VERSION ""

NS_ :

BS_:
BU_: BMC CMC_01 CMC_02 CMC_03 CMC_04 CMC_05 CMC_06 CMC_07 CMC_08 P2_CMC_01 HVBatteryController
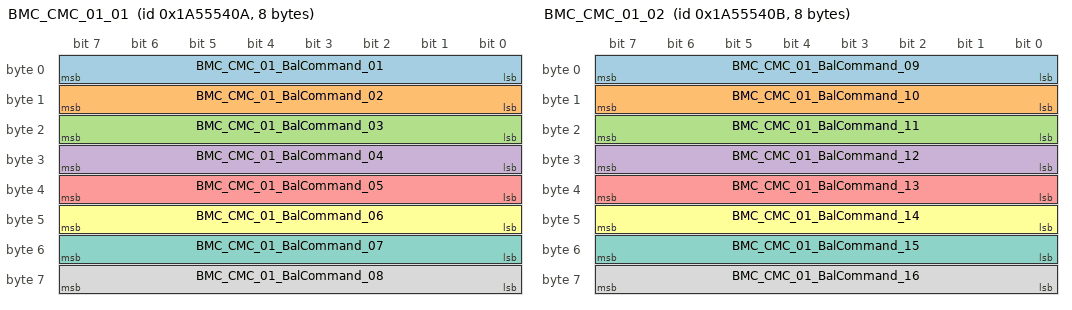
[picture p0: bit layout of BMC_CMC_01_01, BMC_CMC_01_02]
BO_ 441799690 BMC_CMC_01_01: 8 BMC
   SG_ BMC_CMC_01_BalCommand_01 : 0|8@1+ (2,0) [0|506] "Minute" CMC_01
   SG_ BMC_CMC_01_BalCommand_02 : 8|8@1+ (2,0) [0|506] "Minute" CMC_01
   SG_ BMC_CMC_01_BalCommand_03 : 16|8@1+ (2,0) [0|506] "Minute" CMC_01
   SG_ BMC_CMC_01_BalCommand_04 : 24|8@1+ (2,0) [0|506] "Minute" CMC_01
   SG_ BMC_CMC_01_BalCommand_05 : 32|8@1+ (2,0) [0|506] "Minute" CMC_01
   SG_ BMC_CMC_01_BalCommand_06 : 40|8@1+ (2,0) [0|506] "Minute" CMC_01
   SG_ BMC_CMC_01_BalCommand_07 : 48|8@1+ (2,0) [0|506] "Minute" CMC_01
   SG_ BMC_CMC_01_BalCommand_08 : 56|8@1+ (2,0) [0|506] "Minute" CMC_01

BO_ 441799691 BMC_CMC_01_02: 8 BMC
   SG_ BMC_CMC_01_BalCommand_09 : 0|8@1+ (2,0) [0|506] "Minute" CMC_01
   SG_ BMC_CMC_01_BalCommand_10 : 8|8@1+ (2,0) [0|506] "Minute" CMC_01
   SG_ BMC_CMC_01_BalCommand_11 : 16|8@1+ (2,0) [0|506] "Minute" CMC_01
   SG_ BMC_CMC_01_BalCommand_12 : 24|8@1+ (2,0) [0|506] "Minute" CMC_01
   SG_ BMC_CMC_01_BalCommand_13 : 32|8@1+ (2,0) [0|506] "Minute" CMC_01
   SG_ BMC_CMC_01_BalCommand_14 : 40|8@1+ (2,0) [0|506] "Minute" CMC_01
   SG_ BMC_CMC_01_BalCommand_15 : 48|8@1+ (2,0) [0|506] "Minute" CMC_01
   SG_ BMC_CMC_01_BalCommand_16 : 56|8@1+ (2,0) [0|506] "Minute" CMC_01

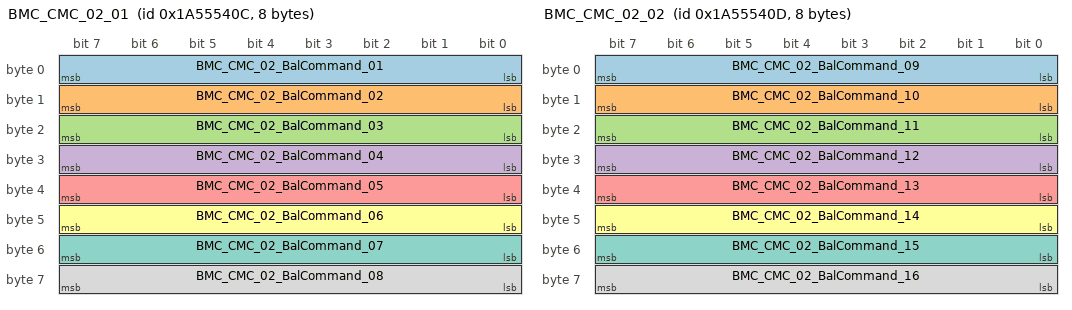
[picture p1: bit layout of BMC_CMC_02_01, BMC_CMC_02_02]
BO_ 441799692 BMC_CMC_02_01: 8 BMC
   SG_ BMC_CMC_02_BalCommand_01 : 0|8@1+ (2,0) [0|506] "Minute" CMC_02
   SG_ BMC_CMC_02_BalCommand_02 : 8|8@1+ (2,0) [0|506] "Minute" CMC_02
   SG_ BMC_CMC_02_BalCommand_03 : 16|8@1+ (2,0) [0|506] "Minute" CMC_02
   SG_ BMC_CMC_02_BalCommand_04 : 24|8@1+ (2,0) [0|506] "Minute" CMC_02
   SG_ BMC_CMC_02_BalCommand_05 : 32|8@1+ (2,0) [0|506] "Minute" CMC_02
   SG_ BMC_CMC_02_BalCommand_06 : 40|8@1+ (2,0) [0|506] "Minute" CMC_02
   SG_ BMC_CMC_02_BalCommand_07 : 48|8@1+ (2,0) [0|506] "Minute" CMC_02
   SG_ BMC_CMC_02_BalCommand_08 : 56|8@1+ (2,0) [0|506] "Minute" CMC_02

BO_ 441799693 BMC_CMC_02_02: 8 BMC
   SG_ BMC_CMC_02_BalCommand_09 : 0|8@1+ (2,0) [0|506] "Minute" CMC_02
   SG_ BMC_CMC_02_BalCommand_10 : 8|8@1+ (2,0) [0|506] "Minute" CMC_02
   SG_ BMC_CMC_02_BalCommand_11 : 16|8@1+ (2,0) [0|506] "Minute" CMC_02
   SG_ BMC_CMC_02_BalCommand_12 : 24|8@1+ (2,0) [0|506] "Minute" CMC_02
   SG_ BMC_CMC_02_BalCommand_13 : 32|8@1+ (2,0) [0|506] "Minute" CMC_02
   SG_ BMC_CMC_02_BalCommand_14 : 40|8@1+ (2,0) [0|506] "Minute" CMC_02
   SG_ BMC_CMC_02_BalCommand_15 : 48|8@1+ (2,0) [0|506] "Minute" CMC_02
   SG_ BMC_CMC_02_BalCommand_16 : 56|8@1+ (2,0) [0|506] "Minute" CMC_02

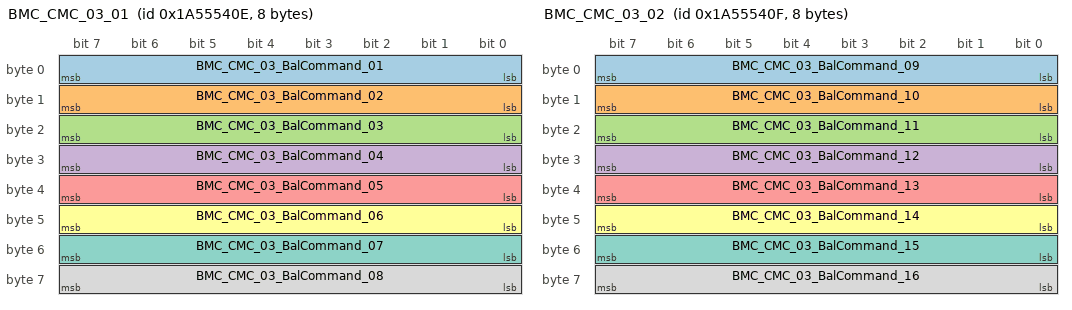
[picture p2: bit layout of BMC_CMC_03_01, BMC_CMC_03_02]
BO_ 441799694 BMC_CMC_03_01: 8 BMC
   SG_ BMC_CMC_03_BalCommand_01 : 0|8@1+ (2,0) [0|506] "Minute" CMC_03
   SG_ BMC_CMC_03_BalCommand_02 : 8|8@1+ (2,0) [0|506] "Minute" CMC_03
   SG_ BMC_CMC_03_BalCommand_03 : 16|8@1+ (2,0) [0|506] "Minute" CMC_03
   SG_ BMC_CMC_03_BalCommand_04 : 24|8@1+ (2,0) [0|506] "Minute" CMC_03
   SG_ BMC_CMC_03_BalCommand_05 : 32|8@1+ (2,0) [0|506] "Minute" CMC_03
   SG_ BMC_CMC_03_BalCommand_06 : 40|8@1+ (2,0) [0|506] "Minute" CMC_03
   SG_ BMC_CMC_03_BalCommand_07 : 48|8@1+ (2,0) [0|506] "Minute" CMC_03
   SG_ BMC_CMC_03_BalCommand_08 : 56|8@1+ (2,0) [0|506] "Minute" CMC_03

BO_ 441799695 BMC_CMC_03_02: 8 BMC
   SG_ BMC_CMC_03_BalCommand_09 : 0|8@1+ (2,0) [0|506] "Minute" CMC_03
   SG_ BMC_CMC_03_BalCommand_10 : 8|8@1+ (2,0) [0|506] "Minute" CMC_03
   SG_ BMC_CMC_03_BalCommand_11 : 16|8@1+ (2,0) [0|506] "Minute" CMC_03
   SG_ BMC_CMC_03_BalCommand_12 : 24|8@1+ (2,0) [0|506] "Minute" CMC_03
   SG_ BMC_CMC_03_BalCommand_13 : 32|8@1+ (2,0) [0|506] "Minute" CMC_03
   SG_ BMC_CMC_03_BalCommand_14 : 40|8@1+ (2,0) [0|506] "Minute" CMC_03
   SG_ BMC_CMC_03_BalCommand_15 : 48|8@1+ (2,0) [0|506] "Minute" CMC_03
   SG_ BMC_CMC_03_BalCommand_16 : 56|8@1+ (2,0) [0|506] "Minute" CMC_03

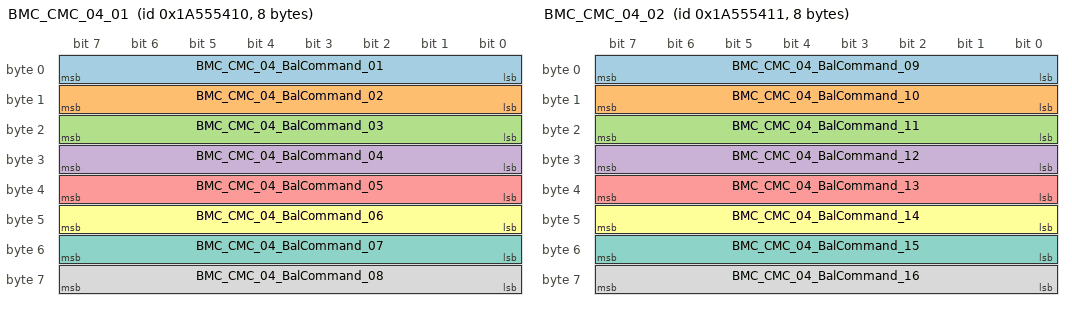
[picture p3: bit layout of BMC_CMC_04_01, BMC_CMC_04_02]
BO_ 441799696 BMC_CMC_04_01: 8 BMC
   SG_ BMC_CMC_04_BalCommand_01 : 0|8@1+ (2,0) [0|506] "Minute" CMC_04
   SG_ BMC_CMC_04_BalCommand_02 : 8|8@1+ (2,0) [0|506] "Minute" CMC_04
   SG_ BMC_CMC_04_BalCommand_03 : 16|8@1+ (2,0) [0|506] "Minute" CMC_04
   SG_ BMC_CMC_04_BalCommand_04 : 24|8@1+ (2,0) [0|506] "Minute" CMC_04
   SG_ BMC_CMC_04_BalCommand_05 : 32|8@1+ (2,0) [0|506] "Minute" CMC_04
   SG_ BMC_CMC_04_BalCommand_06 : 40|8@1+ (2,0) [0|506] "Minute" CMC_04
   SG_ BMC_CMC_04_BalCommand_07 : 48|8@1+ (2,0) [0|506] "Minute" CMC_04
   SG_ BMC_CMC_04_BalCommand_08 : 56|8@1+ (2,0) [0|506] "Minute" CMC_04

BO_ 441799697 BMC_CMC_04_02: 8 BMC
   SG_ BMC_CMC_04_BalCommand_09 : 0|8@1+ (2,0) [0|506] "Minute" CMC_04
   SG_ BMC_CMC_04_BalCommand_10 : 8|8@1+ (2,0) [0|506] "Minute" CMC_04
   SG_ BMC_CMC_04_BalCommand_11 : 16|8@1+ (2,0) [0|506] "Minute" CMC_04
   SG_ BMC_CMC_04_BalCommand_12 : 24|8@1+ (2,0) [0|506] "Minute" CMC_04
   SG_ BMC_CMC_04_BalCommand_13 : 32|8@1+ (2,0) [0|506] "Minute" CMC_04
   SG_ BMC_CMC_04_BalCommand_14 : 40|8@1+ (2,0) [0|506] "Minute" CMC_04
   SG_ BMC_CMC_04_BalCommand_15 : 48|8@1+ (2,0) [0|506] "Minute" CMC_04
   SG_ BMC_CMC_04_BalCommand_16 : 56|8@1+ (2,0) [0|506] "Minute" CMC_04

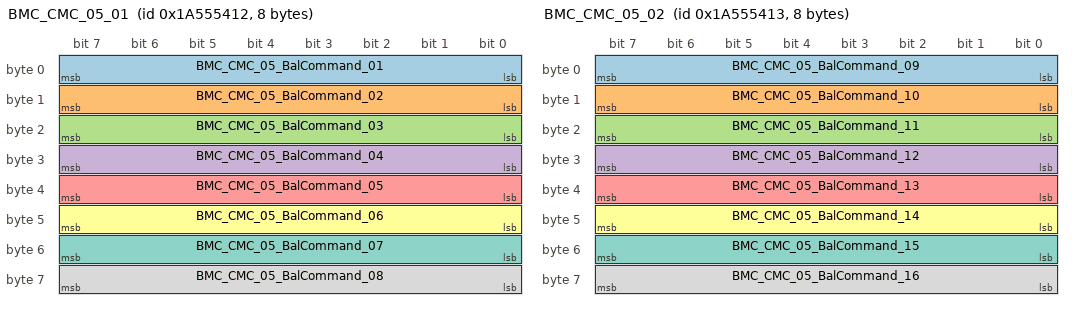
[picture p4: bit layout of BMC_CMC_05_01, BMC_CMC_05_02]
BO_ 441799698 BMC_CMC_05_01: 8 BMC
   SG_ BMC_CMC_05_BalCommand_01 : 0|8@1+ (2,0) [0|506] "Minute" CMC_05
   SG_ BMC_CMC_05_BalCommand_02 : 8|8@1+ (2,0) [0|506] "Minute" CMC_05
   SG_ BMC_CMC_05_BalCommand_03 : 16|8@1+ (2,0) [0|506] "Minute" CMC_05
   SG_ BMC_CMC_05_BalCommand_04 : 24|8@1+ (2,0) [0|506] "Minute" CMC_05
   SG_ BMC_CMC_05_BalCommand_05 : 32|8@1+ (2,0) [0|506] "Minute" CMC_05
   SG_ BMC_CMC_05_BalCommand_06 : 40|8@1+ (2,0) [0|506] "Minute" CMC_05
   SG_ BMC_CMC_05_BalCommand_07 : 48|8@1+ (2,0) [0|506] "Minute" CMC_05
   SG_ BMC_CMC_05_BalCommand_08 : 56|8@1+ (2,0) [0|506] "Minute" CMC_05

BO_ 441799699 BMC_CMC_05_02: 8 BMC
   SG_ BMC_CMC_05_BalCommand_09 : 0|8@1+ (2,0) [0|506] "Minute" CMC_05
   SG_ BMC_CMC_05_BalCommand_10 : 8|8@1+ (2,0) [0|506] "Minute" CMC_05
   SG_ BMC_CMC_05_BalCommand_11 : 16|8@1+ (2,0) [0|506] "Minute" CMC_05
   SG_ BMC_CMC_05_BalCommand_12 : 24|8@1+ (2,0) [0|506] "Minute" CMC_05
   SG_ BMC_CMC_05_BalCommand_13 : 32|8@1+ (2,0) [0|506] "Minute" CMC_05
   SG_ BMC_CMC_05_BalCommand_14 : 40|8@1+ (2,0) [0|506] "Minute" CMC_05
   SG_ BMC_CMC_05_BalCommand_15 : 48|8@1+ (2,0) [0|506] "Minute" CMC_05
   SG_ BMC_CMC_05_BalCommand_16 : 56|8@1+ (2,0) [0|506] "Minute" CMC_05

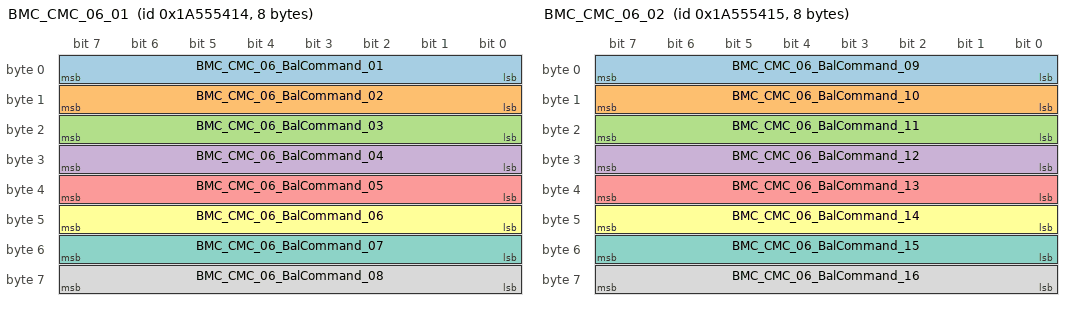
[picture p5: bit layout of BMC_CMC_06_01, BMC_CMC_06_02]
BO_ 441799700 BMC_CMC_06_01: 8 BMC
   SG_ BMC_CMC_06_BalCommand_01 : 0|8@1+ (2,0) [0|506] "Minute" CMC_06
   SG_ BMC_CMC_06_BalCommand_02 : 8|8@1+ (2,0) [0|506] "Minute" CMC_06
   SG_ BMC_CMC_06_BalCommand_03 : 16|8@1+ (2,0) [0|506] "Minute" CMC_06
   SG_ BMC_CMC_06_BalCommand_04 : 24|8@1+ (2,0) [0|506] "Minute" CMC_06
   SG_ BMC_CMC_06_BalCommand_05 : 32|8@1+ (2,0) [0|506] "Minute" CMC_06
   SG_ BMC_CMC_06_BalCommand_06 : 40|8@1+ (2,0) [0|506] "Minute" CMC_06
   SG_ BMC_CMC_06_BalCommand_07 : 48|8@1+ (2,0) [0|506] "Minute" CMC_06
   SG_ BMC_CMC_06_BalCommand_08 : 56|8@1+ (2,0) [0|506] "Minute" CMC_06

BO_ 441799701 BMC_CMC_06_02: 8 BMC
   SG_ BMC_CMC_06_BalCommand_09 : 0|8@1+ (2,0) [0|506] "Minute" CMC_06
   SG_ BMC_CMC_06_BalCommand_10 : 8|8@1+ (2,0) [0|506] "Minute" CMC_06
   SG_ BMC_CMC_06_BalCommand_11 : 16|8@1+ (2,0) [0|506] "Minute" CMC_06
   SG_ BMC_CMC_06_BalCommand_12 : 24|8@1+ (2,0) [0|506] "Minute" CMC_06
   SG_ BMC_CMC_06_BalCommand_13 : 32|8@1+ (2,0) [0|506] "Minute" CMC_06
   SG_ BMC_CMC_06_BalCommand_14 : 40|8@1+ (2,0) [0|506] "Minute" CMC_06
   SG_ BMC_CMC_06_BalCommand_15 : 48|8@1+ (2,0) [0|506] "Minute" CMC_06
   SG_ BMC_CMC_06_BalCommand_16 : 56|8@1+ (2,0) [0|506] "Minute" CMC_06

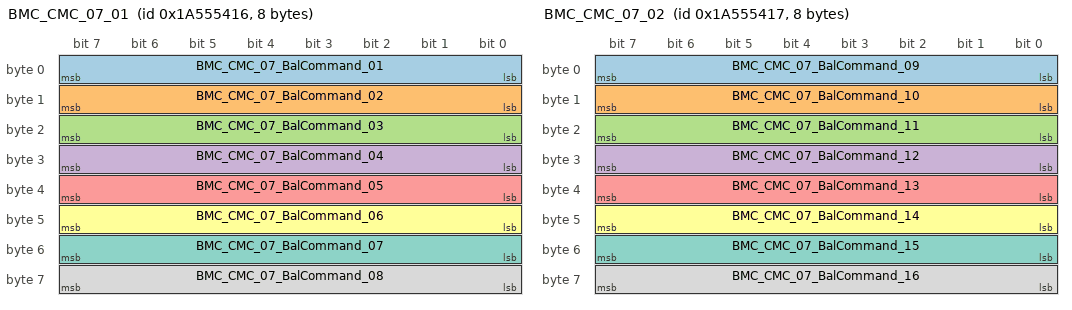
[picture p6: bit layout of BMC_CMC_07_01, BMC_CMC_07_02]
BO_ 441799702 BMC_CMC_07_01: 8 BMC
   SG_ BMC_CMC_07_BalCommand_01 : 0|8@1+ (2,0) [0|506] "Minute" CMC_07
   SG_ BMC_CMC_07_BalCommand_02 : 8|8@1+ (2,0) [0|506] "Minute" CMC_07
   SG_ BMC_CMC_07_BalCommand_03 : 16|8@1+ (2,0) [0|506] "Minute" CMC_07
   SG_ BMC_CMC_07_BalCommand_04 : 24|8@1+ (2,0) [0|506] "Minute" CMC_07
   SG_ BMC_CMC_07_BalCommand_05 : 32|8@1+ (2,0) [0|506] "Minute" CMC_07
   SG_ BMC_CMC_07_BalCommand_06 : 40|8@1+ (2,0) [0|506] "Minute" CMC_07
   SG_ BMC_CMC_07_BalCommand_07 : 48|8@1+ (2,0) [0|506] "Minute" CMC_07
   SG_ BMC_CMC_07_BalCommand_08 : 56|8@1+ (2,0) [0|506] "Minute" CMC_07

BO_ 441799703 BMC_CMC_07_02: 8 BMC
   SG_ BMC_CMC_07_BalCommand_09 : 0|8@1+ (2,0) [0|506] "Minute" CMC_07
   SG_ BMC_CMC_07_BalCommand_10 : 8|8@1+ (2,0) [0|506] "Minute" CMC_07
   SG_ BMC_CMC_07_BalCommand_11 : 16|8@1+ (2,0) [0|506] "Minute" CMC_07
   SG_ BMC_CMC_07_BalCommand_12 : 24|8@1+ (2,0) [0|506] "Minute" CMC_07
   SG_ BMC_CMC_07_BalCommand_13 : 32|8@1+ (2,0) [0|506] "Minute" CMC_07
   SG_ BMC_CMC_07_BalCommand_14 : 40|8@1+ (2,0) [0|506] "Minute" CMC_07
   SG_ BMC_CMC_07_BalCommand_15 : 48|8@1+ (2,0) [0|506] "Minute" CMC_07
   SG_ BMC_CMC_07_BalCommand_16 : 56|8@1+ (2,0) [0|506] "Minute" CMC_07

BO_ 441799704 BMC_CMC_08_01: 8 BMC
   SG_ CMC_08_Cell01Balance : 63|1@1+ (1,0) [0|1] "" Vector__XXX
   SG_ BMC_CMC_08_BalCommand_01 : 0|8@1+ (2,0) [0|506] "Minute" CMC_08
   SG_ BMC_CMC_08_BalCommand_02 : 8|8@1+ (2,0) [0|506] "Minute" CMC_08
   SG_ BMC_CMC_08_BalCommand_03 : 16|8@1+ (2,0) [0|506] "Minute" CMC_08
   SG_ BMC_CMC_08_BalCommand_04 : 24|8@1+ (2,0) [0|506] "Minute" CMC_08
   SG_ BMC_CMC_08_BalCommand_05 : 32|8@1+ (2,0) [0|506] "Minute" CMC_08
   SG_ BMC_CMC_08_BalCommand_06 : 40|8@1+ (2,0) [0|506] "Minute" CMC_08
   SG_ BMC_CMC_08_BalCommand_07 : 48|8@1+ (2,0) [0|506] "Minute" CMC_08
   SG_ BMC_CMC_08_BalCommand_08 : 56|8@1+ (2,0) [0|506] "Minute" CMC_08

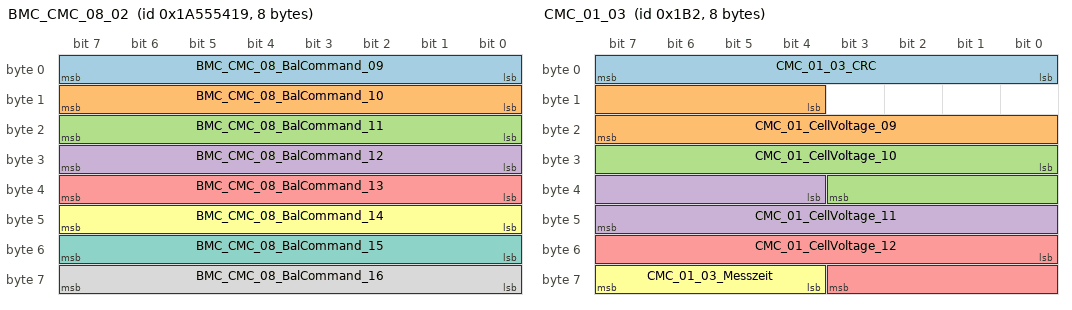
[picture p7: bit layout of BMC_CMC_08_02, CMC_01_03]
BO_ 441799705 BMC_CMC_08_02: 8 BMC
   SG_ BMC_CMC_08_BalCommand_09 : 0|8@1+ (2,0) [0|506] "Minute" CMC_08
   SG_ BMC_CMC_08_BalCommand_10 : 8|8@1+ (2,0) [0|506] "Minute" CMC_08
   SG_ BMC_CMC_08_BalCommand_11 : 16|8@1+ (2,0) [0|506] "Minute" CMC_08
   SG_ BMC_CMC_08_BalCommand_12 : 24|8@1+ (2,0) [0|506] "Minute" CMC_08
   SG_ BMC_CMC_08_BalCommand_13 : 32|8@1+ (2,0) [0|506] "Minute" CMC_08
   SG_ BMC_CMC_08_BalCommand_14 : 40|8@1+ (2,0) [0|506] "Minute" CMC_08
   SG_ BMC_CMC_08_BalCommand_15 : 48|8@1+ (2,0) [0|506] "Minute" CMC_08
   SG_ BMC_CMC_08_BalCommand_16 : 56|8@1+ (2,0) [0|506] "Minute" CMC_08

BO_ 432 CMC_01_01: 8 CMC_01
   SG_ CMC_01_01_CRC : 0|8@1+ (1,0) [0|255] "" BMC
   SG_ CMC_01_CellVoltage_01 : 12|12@1+ (1,1000) [1000|5091] "MilliVolt" BMC
   SG_ CMC_01_CellVoltage_02 : 24|12@1+ (1,1000) [1000|5091] "MilliVolt" BMC
   SG_ CMC_01_CellVoltage_03 : 36|12@1+ (1,1000) [1000|5091] "MilliVolt" BMC
   SG_ CMC_01_CellVoltage_04 : 48|12@1+ (1,1000) [1000|5091] "MilliVolt" BMC

BO_ 433 CMC_01_02: 8 CMC_01
   SG_ CMC_01_02_CRC : 0|8@1+ (1,0) [0|255] "" BMC
   SG_ CMC_01_CellVoltage_05 : 12|12@1+ (1,1000) [1000|5091] "MilliVolt" BMC
   SG_ CMC_01_CellVoltage_06 : 24|12@1+ (1,1000) [1000|5091] "MilliVolt" BMC
   SG_ CMC_01_CellVoltage_07 : 36|12@1+ (1,1000) [1000|5091] "MilliVolt" BMC
   SG_ CMC_01_CellVoltage_08 : 48|12@1+ (1,1000) [1000|5091] "MilliVolt" BMC

BO_ 434 CMC_01_03: 8 CMC_01
   SG_ CMC_01_03_CRC : 0|8@1+ (1,0) [0|255] "" BMC
   SG_ CMC_01_CellVoltage_09 : 12|12@1+ (1,1000) [1000|5091] "MilliVolt" BMC
   SG_ CMC_01_CellVoltage_10 : 24|12@1+ (1,1000) [1000|5091] "MilliVolt" BMC
   SG_ CMC_01_CellVoltage_11 : 36|12@1+ (1,1000) [1000|5091] "MilliVolt" BMC
   SG_ CMC_01_CellVoltage_12 : 48|12@1+ (1,1000) [1000|5091] "MilliVolt" BMC
   SG_ CMC_01_03_Messzeit : 60|4@1+ (1,0) [0|14] "Unit_None" BMC

BO_ 464 P2_CMC_01_01: 8 P2_CMC_01
   SG_ P2_CMC_01_01_CRC : 0|8@1+ (1,0) [0|255] "" BMC
   SG_ P2_CMC_01_CellVoltage_01 : 12|12@1+ (1,1000) [1000|5091] "MilliVolt" BMC
   SG_ P2_CMC_01_CellVoltage_02 : 24|12@1+ (1,1000) [1000|5091] "MilliVolt" BMC
   SG_ P2_CMC_01_CellVoltage_03 : 36|12@1+ (1,1000) [1000|5091] "MilliVolt" BMC
   SG_ P2_CMC_01_CellVoltage_04 : 48|12@1+ (1,1000) [1000|5091] "MilliVolt" BMC

BO_ 465 P2_CMC_01_02: 8 P2_CMC_01
   SG_ P2_CMC_01_02_CRC : 0|8@1+ (1,0) [0|255] "" BMC
   SG_ P2_CMC_01_CellVoltage_05 : 12|12@1+ (1,1000) [1000|5091] "MilliVolt" BMC
   SG_ P2_CMC_01_CellVoltage_06 : 24|12@1+ (1,1000) [1000|5091] "MilliVolt" BMC
   SG_ P2_CMC_01_CellVoltage_07 : 36|12@1+ (1,1000) [1000|5091] "MilliVolt" BMC
   SG_ P2_CMC_01_CellVoltage_08 : 48|12@1+ (1,1000) [1000|5091] "MilliVolt" BMC

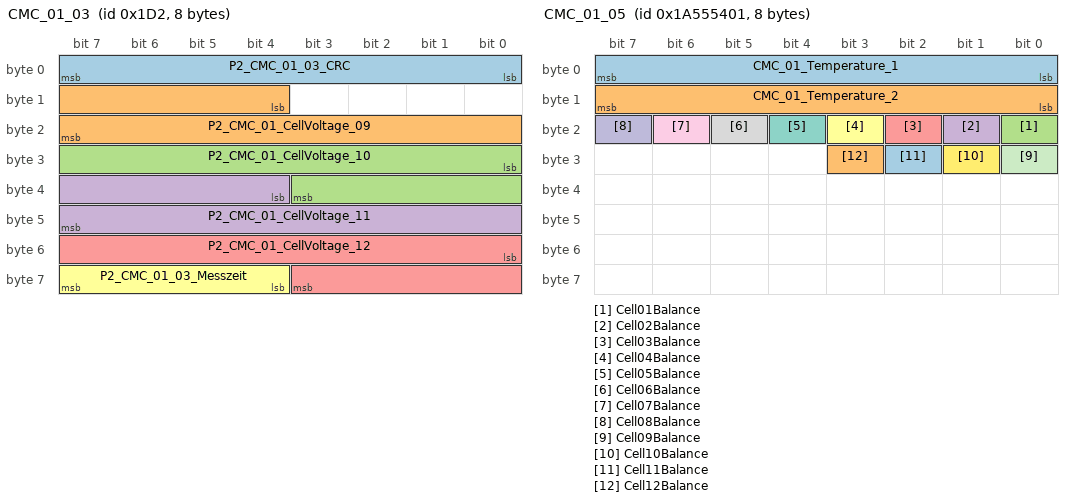
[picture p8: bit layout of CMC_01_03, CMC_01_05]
BO_ 466 CMC_01_03: 8 P2_CMC_01
   SG_ P2_CMC_01_03_CRC : 0|8@1+ (1,0) [0|255] "" BMC
   SG_ P2_CMC_01_CellVoltage_09 : 12|12@1+ (1,1000) [1000|5091] "MilliVolt" BMC
   SG_ P2_CMC_01_CellVoltage_10 : 24|12@1+ (1,1000) [1000|5091] "MilliVolt" BMC
   SG_ P2_CMC_01_CellVoltage_11 : 36|12@1+ (1,1000) [1000|5091] "MilliVolt" BMC
   SG_ P2_CMC_01_CellVoltage_12 : 48|12@1+ (1,1000) [1000|5091] "MilliVolt" BMC
   SG_ P2_CMC_01_03_Messzeit : 60|4@1+ (1,0) [0|14] "Unit_None" BMC

BO_ 441799681 CMC_01_05: 8 CMC_01
   SG_ CMC_01_Temperature_1 : 0|8@1+ (0.5,-40) [-40|86] "DegreeCelcius" BMC
   SG_ CMC_01_Temperature_2 : 8|8@1+ (0.5,-40) [-40|86] "DegreeCelcius" BMC
   SG_ Cell01Balance : 16|1@1+ (1,0) [0|0] "" Vector__XXX
   SG_ Cell02Balance : 17|1@1+ (1,0) [0|0] "" Vector__XXX
   SG_ Cell03Balance : 18|1@1+ (1,0) [0|0] "" Vector__XXX
   SG_ Cell04Balance : 19|1@1+ (1,0) [0|0] "" Vector__XXX
   SG_ Cell05Balance : 20|1@1+ (1,0) [0|0] "" Vector__XXX
   SG_ Cell06Balance : 21|1@1+ (1,0) [0|0] "" Vector__XXX
   SG_ Cell07Balance : 22|1@1+ (1,0) [0|0] "" Vector__XXX
   SG_ Cell08Balance : 23|1@1+ (1,0) [0|0] "" Vector__XXX
   SG_ Cell09Balance : 24|1@1+ (1,0) [0|0] "" Vector__XXX
   SG_ Cell10Balance : 25|1@1+ (1,0) [0|0] "" Vector__XXX
   SG_ Cell11Balance : 26|1@1+ (1,0) [0|0] "" Vector__XXX
   SG_ Cell12Balance : 27|1@1+ (1,0) [0|0] "" Vector__XXX

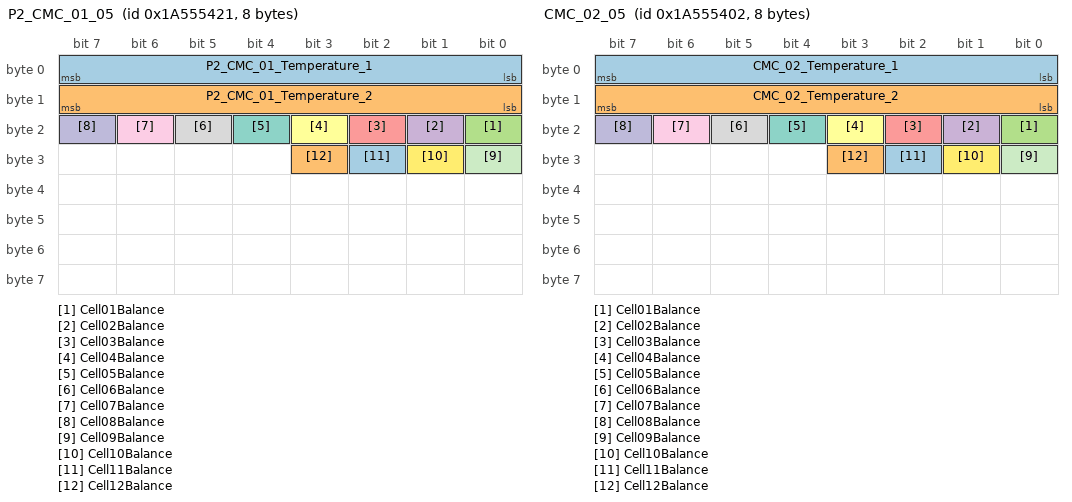
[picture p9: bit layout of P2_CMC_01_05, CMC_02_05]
BO_ 441799713 P2_CMC_01_05: 8 P2_CMC_01
   SG_ P2_CMC_01_Temperature_1 : 0|8@1+ (0.5,-40) [-40|86] "DegreeCelcius" BMC
   SG_ P2_CMC_01_Temperature_2 : 8|8@1+ (0.5,-40) [-40|86] "DegreeCelcius" BMC
   SG_ Cell01Balance : 16|1@1+ (1,0) [0|0] "" Vector__XXX
   SG_ Cell02Balance : 17|1@1+ (1,0) [0|0] "" Vector__XXX
   SG_ Cell03Balance : 18|1@1+ (1,0) [0|0] "" Vector__XXX
   SG_ Cell04Balance : 19|1@1+ (1,0) [0|0] "" Vector__XXX
   SG_ Cell05Balance : 20|1@1+ (1,0) [0|0] "" Vector__XXX
   SG_ Cell06Balance : 21|1@1+ (1,0) [0|0] "" Vector__XXX
   SG_ Cell07Balance : 22|1@1+ (1,0) [0|0] "" Vector__XXX
   SG_ Cell08Balance : 23|1@1+ (1,0) [0|0] "" Vector__XXX
   SG_ Cell09Balance : 24|1@1+ (1,0) [0|0] "" Vector__XXX
   SG_ Cell10Balance : 25|1@1+ (1,0) [0|0] "" Vector__XXX
   SG_ Cell11Balance : 26|1@1+ (1,0) [0|0] "" Vector__XXX
   SG_ Cell12Balance : 27|1@1+ (1,0) [0|0] "" Vector__XXX

BO_ 436 CMC_02_01: 8 CMC_02
   SG_ CMC_02_01_CRC : 0|8@1+ (1,0) [0|255] "" BMC
   SG_ CMC_02_CellVoltage_01 : 12|12@1+ (1,1000) [1000|5091] "MilliVolt" BMC
   SG_ CMC_02_CellVoltage_02 : 24|12@1+ (1,1000) [1000|5091] "MilliVolt" BMC
   SG_ CMC_02_CellVoltage_03 : 36|12@1+ (1,1000) [1000|5091] "MilliVolt" BMC
   SG_ CMC_02_CellVoltage_04 : 48|12@1+ (1,1000) [1000|5091] "MilliVolt" BMC

BO_ 437 CMC_02_02: 8 CMC_02
   SG_ CMC_02_02_CRC : 0|8@1+ (1,0) [0|255] "" BMC
   SG_ CMC_02_CellVoltage_05 : 12|12@1+ (1,1000) [1000|5091] "MilliVolt" BMC
   SG_ CMC_02_CellVoltage_06 : 24|12@1+ (1,1000) [1000|5091] "MilliVolt" BMC
   SG_ CMC_02_CellVoltage_07 : 36|12@1+ (1,1000) [1000|5091] "MilliVolt" BMC
   SG_ CMC_02_CellVoltage_08 : 48|12@1+ (1,1000) [1000|5091] "MilliVolt" BMC

BO_ 438 CMC_02_03: 8 CMC_02
   SG_ CMC_02_03_CRC : 0|8@1+ (1,0) [0|255] "" BMC
   SG_ CMC_02_CellVoltage_09 : 12|12@1+ (1,1000) [1000|5091] "MilliVolt" BMC
   SG_ CMC_02_CellVoltage_10 : 24|12@1+ (1,1000) [1000|5091] "MilliVolt" BMC
   SG_ CMC_02_CellVoltage_11 : 36|12@1+ (1,1000) [1000|5091] "MilliVolt" BMC
   SG_ CMC_02_CellVoltage_12 : 48|12@1+ (1,1000) [1000|5091] "MilliVolt" BMC

BO_ 468 P2_CMC_02_01: 8 Vector__XXX
   SG_ P2_CMC_02_01_CRC : 0|8@1+ (1,0) [0|255] "" BMC
   SG_ P2_CMC_02_CellVoltage_01 : 12|12@1+ (1,1000) [1000|5091] "MilliVolt" BMC
   SG_ P2_CMC_02_CellVoltage_02 : 24|12@1+ (1,1000) [1000|5091] "MilliVolt" BMC
   SG_ P2_CMC_02_CellVoltage_03 : 36|12@1+ (1,1000) [1000|5091] "MilliVolt" BMC
   SG_ P2_CMC_02_CellVoltage_04 : 48|12@1+ (1,1000) [1000|5091] "MilliVolt" BMC

BO_ 469 P2_CMC_02_02: 8 Vector__XXX
   SG_ P2_CMC_02_02_CRC : 0|8@1+ (1,0) [0|255] "" BMC
   SG_ P2_CMC_02_CellVoltage_05 : 12|12@1+ (1,1000) [1000|5091] "MilliVolt" BMC
   SG_ P2_CMC_02_CellVoltage_06 : 24|12@1+ (1,1000) [1000|5091] "MilliVolt" BMC
   SG_ P2_CMC_02_CellVoltage_07 : 36|12@1+ (1,1000) [1000|5091] "MilliVolt" BMC
   SG_ P2_CMC_02_CellVoltage_08 : 48|12@1+ (1,1000) [1000|5091] "MilliVolt" BMC

BO_ 470 CMC_02_03: 8 Vector__XXX
   SG_ P2_CMC_02_03_CRC : 0|8@1+ (1,0) [0|255] "" BMC
   SG_ P2_CMC_02_CellVoltage_09 : 12|12@1+ (1,1000) [1000|5091] "MilliVolt" BMC
   SG_ P2_CMC_02_CellVoltage_10 : 24|12@1+ (1,1000) [1000|5091] "MilliVolt" BMC
   SG_ P2_CMC_02_CellVoltage_11 : 36|12@1+ (1,1000) [1000|5091] "MilliVolt" BMC
   SG_ P2_CMC_02_CellVoltage_12 : 48|12@1+ (1,1000) [1000|5091] "MilliVolt" BMC

BO_ 441799682 CMC_02_05: 8 CMC_02
   SG_ CMC_02_Temperature_1 : 0|8@1+ (0.5,-40) [-40|86] "DegreeCelcius" BMC
   SG_ CMC_02_Temperature_2 : 8|8@1+ (0.5,-40) [-40|86] "DegreeCelcius" BMC
   SG_ Cell01Balance : 16|1@1+ (1,0) [0|0] "" Vector__XXX
   SG_ Cell02Balance : 17|1@1+ (1,0) [0|0] "" Vector__XXX
   SG_ Cell03Balance : 18|1@1+ (1,0) [0|0] "" Vector__XXX
   SG_ Cell04Balance : 19|1@1+ (1,0) [0|0] "" Vector__XXX
   SG_ Cell05Balance : 20|1@1+ (1,0) [0|0] "" Vector__XXX
   SG_ Cell06Balance : 21|1@1+ (1,0) [0|0] "" Vector__XXX
   SG_ Cell07Balance : 22|1@1+ (1,0) [0|0] "" Vector__XXX
   SG_ Cell08Balance : 23|1@1+ (1,0) [0|0] "" Vector__XXX
   SG_ Cell09Balance : 24|1@1+ (1,0) [0|0] "" Vector__XXX
   SG_ Cell10Balance : 25|1@1+ (1,0) [0|0] "" Vector__XXX
   SG_ Cell11Balance : 26|1@1+ (1,0) [0|0] "" Vector__XXX
   SG_ Cell12Balance : 27|1@1+ (1,0) [0|0] "" Vector__XXX

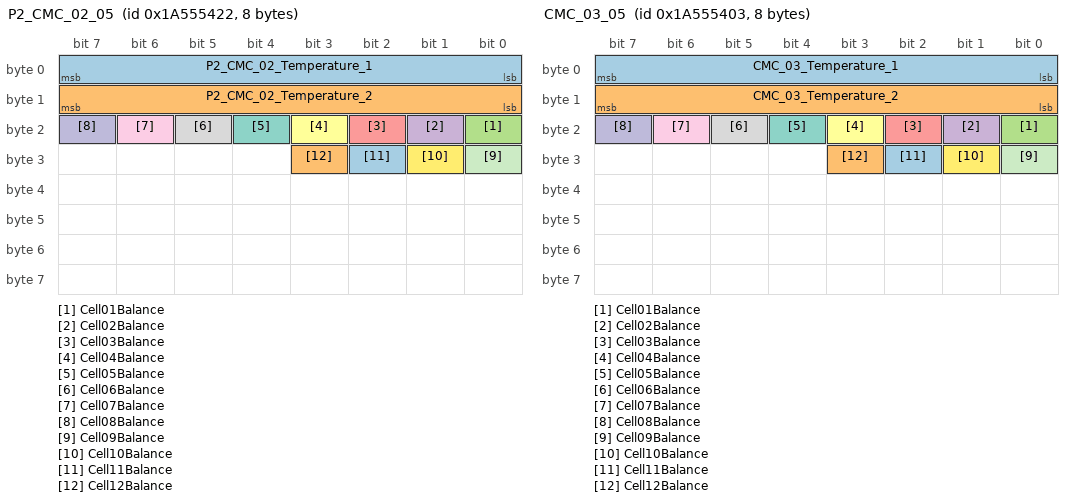
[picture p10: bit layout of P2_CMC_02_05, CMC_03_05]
BO_ 441799714 P2_CMC_02_05: 8 Vector__XXX
   SG_ P2_CMC_02_Temperature_1 : 0|8@1+ (0.5,-40) [-40|86] "DegreeCelcius" BMC
   SG_ P2_CMC_02_Temperature_2 : 8|8@1+ (0.5,-40) [-40|86] "DegreeCelcius" BMC
   SG_ Cell01Balance : 16|1@1+ (1,0) [0|0] "" Vector__XXX
   SG_ Cell02Balance : 17|1@1+ (1,0) [0|0] "" Vector__XXX
   SG_ Cell03Balance : 18|1@1+ (1,0) [0|0] "" Vector__XXX
   SG_ Cell04Balance : 19|1@1+ (1,0) [0|0] "" Vector__XXX
   SG_ Cell05Balance : 20|1@1+ (1,0) [0|0] "" Vector__XXX
   SG_ Cell06Balance : 21|1@1+ (1,0) [0|0] "" Vector__XXX
   SG_ Cell07Balance : 22|1@1+ (1,0) [0|0] "" Vector__XXX
   SG_ Cell08Balance : 23|1@1+ (1,0) [0|0] "" Vector__XXX
   SG_ Cell09Balance : 24|1@1+ (1,0) [0|0] "" Vector__XXX
   SG_ Cell10Balance : 25|1@1+ (1,0) [0|0] "" Vector__XXX
   SG_ Cell11Balance : 26|1@1+ (1,0) [0|0] "" Vector__XXX
   SG_ Cell12Balance : 27|1@1+ (1,0) [0|0] "" Vector__XXX

BO_ 440 CMC_03_01: 8 CMC_03
   SG_ CMC_03_01_CRC : 0|8@1+ (1,0) [0|255] "" BMC
   SG_ CMC_03_CellVoltage_01 : 12|12@1+ (1,1000) [1000|5091] "MilliVolt" BMC
   SG_ CMC_03_CellVoltage_02 : 24|12@1+ (1,1000) [1000|5091] "MilliVolt" BMC
   SG_ CMC_03_CellVoltage_03 : 36|12@1+ (1,1000) [1000|5091] "MilliVolt" BMC
   SG_ CMC_03_CellVoltage_04 : 48|12@1+ (1,1000) [1000|5091] "MilliVolt" BMC

BO_ 441 CMC_03_02: 8 CMC_03
   SG_ CMC_03_02_CRC : 0|8@1+ (1,0) [0|255] "" BMC
   SG_ CMC_03_CellVoltage_05 : 12|12@1+ (1,1000) [1000|5091] "MilliVolt" BMC
   SG_ CMC_03_CellVoltage_06 : 24|12@1+ (1,1000) [1000|5091] "MilliVolt" BMC
   SG_ CMC_03_CellVoltage_07 : 36|12@1+ (1,1000) [1000|5091] "MilliVolt" BMC
   SG_ CMC_03_CellVoltage_08 : 48|12@1+ (1,1000) [1000|5091] "MilliVolt" BMC

BO_ 442 CMC_03_03: 8 CMC_03
   SG_ CMC_03_03_CRC : 0|8@1+ (1,0) [0|255] "" BMC
   SG_ CMC_03_CellVoltage_09 : 12|12@1+ (1,1000) [1000|5091] "MilliVolt" BMC
   SG_ CMC_03_CellVoltage_10 : 24|12@1+ (1,1000) [1000|5091] "MilliVolt" BMC
   SG_ CMC_03_CellVoltage_11 : 36|12@1+ (1,1000) [1000|5091] "MilliVolt" BMC
   SG_ CMC_03_CellVoltage_12 : 48|12@1+ (1,1000) [1000|5091] "MilliVolt" BMC

BO_ 472 P2_CMC_03_01: 8 Vector__XXX
   SG_ P2_CMC_03_01_CRC : 0|8@1+ (1,0) [0|255] "" BMC
   SG_ P2_CMC_03_CellVoltage_01 : 12|12@1+ (1,1000) [1000|5091] "MilliVolt" BMC
   SG_ P2_CMC_03_CellVoltage_02 : 24|12@1+ (1,1000) [1000|5091] "MilliVolt" BMC
   SG_ P2_CMC_03_CellVoltage_03 : 36|12@1+ (1,1000) [1000|5091] "MilliVolt" BMC
   SG_ P2_CMC_03_CellVoltage_04 : 48|12@1+ (1,1000) [1000|5091] "MilliVolt" BMC

BO_ 473 P2_CMC_03_02: 8 Vector__XXX
   SG_ P2_CMC_03_02_CRC : 0|8@1+ (1,0) [0|255] "" BMC
   SG_ P2_CMC_03_CellVoltage_05 : 12|12@1+ (1,1000) [1000|5091] "MilliVolt" BMC
   SG_ P2_CMC_03_CellVoltage_06 : 24|12@1+ (1,1000) [1000|5091] "MilliVolt" BMC
   SG_ P2_CMC_03_CellVoltage_07 : 36|12@1+ (1,1000) [1000|5091] "MilliVolt" BMC
   SG_ P2_CMC_03_CellVoltage_08 : 48|12@1+ (1,1000) [1000|5091] "MilliVolt" BMC

BO_ 474 P2_CMC_03_03: 8 Vector__XXX
   SG_ P2_CMC_03_03_CRC : 0|8@1+ (1,0) [0|255] "" BMC
   SG_ P2_CMC_03_CellVoltage_09 : 12|12@1+ (1,1000) [1000|5091] "MilliVolt" BMC
   SG_ P2_CMC_03_CellVoltage_10 : 24|12@1+ (1,1000) [1000|5091] "MilliVolt" BMC
   SG_ P2_CMC_03_CellVoltage_11 : 36|12@1+ (1,1000) [1000|5091] "MilliVolt" BMC
   SG_ P2_CMC_03_CellVoltage_12 : 48|12@1+ (1,1000) [1000|5091] "MilliVolt" BMC

BO_ 441799683 CMC_03_05: 8 CMC_03
   SG_ CMC_03_Temperature_1 : 0|8@1+ (0.5,-40) [-40|86] "DegreeCelcius" BMC
   SG_ CMC_03_Temperature_2 : 8|8@1+ (0.5,-40) [-40|86] "DegreeCelcius" BMC
   SG_ Cell01Balance : 16|1@1+ (0.5,-40) [-40|86] "DegreeCelcius" BMC
   SG_ Cell02Balance : 17|1@1+ (0.5,-40) [-40|86] "" BMC
   SG_ Cell03Balance : 18|1@1+ (0.5,-40) [-40|86] "" BMC
   SG_ Cell04Balance : 19|1@1+ (0.5,-40) [-40|86] "" BMC
   SG_ Cell05Balance : 20|1@1+ (0.5,-40) [-40|86] "" BMC
   SG_ Cell06Balance : 21|1@1+ (0.5,-40) [-40|86] "" BMC
   SG_ Cell07Balance : 22|1@1+ (0.5,-40) [-40|86] "" BMC
   SG_ Cell08Balance : 23|1@1+ (0.5,-40) [-40|86] "" BMC
   SG_ Cell09Balance : 24|1@1+ (0.5,-40) [-40|86] "" BMC
   SG_ Cell10Balance : 25|1@1+ (0.5,-40) [-40|86] "" BMC
   SG_ Cell11Balance : 26|1@1+ (0.5,-40) [-40|86] "" BMC
   SG_ Cell12Balance : 27|1@1+ (0.5,-40) [-40|86] "" BMC

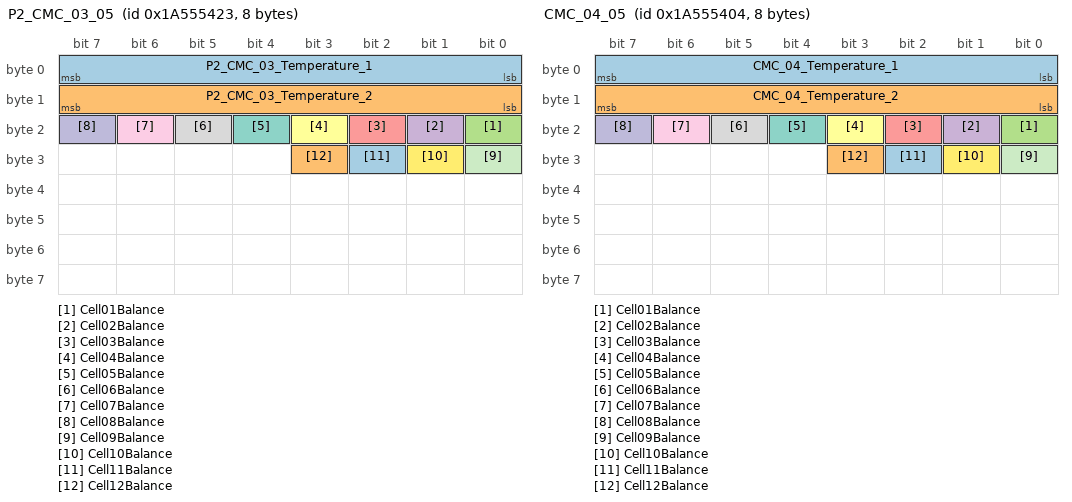
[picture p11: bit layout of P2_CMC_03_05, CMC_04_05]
BO_ 441799715 P2_CMC_03_05: 8 Vector__XXX
   SG_ P2_CMC_03_Temperature_1 : 0|8@1+ (0.5,-40) [-40|86] "DegreeCelcius" BMC
   SG_ P2_CMC_03_Temperature_2 : 8|8@1+ (0.5,-40) [-40|86] "DegreeCelcius" BMC
   SG_ Cell01Balance : 16|1@1+ (1,0) [0|0] "" Vector__XXX
   SG_ Cell02Balance : 17|1@1+ (1,0) [0|0] "" Vector__XXX
   SG_ Cell03Balance : 18|1@1+ (1,0) [0|0] "" Vector__XXX
   SG_ Cell04Balance : 19|1@1+ (1,0) [0|0] "" Vector__XXX
   SG_ Cell05Balance : 20|1@1+ (1,0) [0|0] "" Vector__XXX
   SG_ Cell06Balance : 21|1@1+ (1,0) [0|0] "" Vector__XXX
   SG_ Cell07Balance : 22|1@1+ (1,0) [0|0] "" Vector__XXX
   SG_ Cell08Balance : 23|1@1+ (1,0) [0|0] "" Vector__XXX
   SG_ Cell09Balance : 24|1@1+ (1,0) [0|0] "" Vector__XXX
   SG_ Cell10Balance : 25|1@1+ (1,0) [0|0] "" Vector__XXX
   SG_ Cell11Balance : 26|1@1+ (1,0) [0|0] "" Vector__XXX
   SG_ Cell12Balance : 27|1@1+ (1,0) [0|0] "" Vector__XXX

BO_ 444 CMC_04_01: 8 CMC_04
   SG_ CMC_04_01_CRC : 0|8@1+ (1,0) [0|255] "" BMC
   SG_ CMC_04_CellVoltage_01 : 12|12@1+ (1,1000) [1000|5091] "MilliVolt" BMC
   SG_ CMC_04_CellVoltage_02 : 24|12@1+ (1,1000) [1000|5091] "MilliVolt" BMC
   SG_ CMC_04_CellVoltage_03 : 36|12@1+ (1,1000) [1000|5091] "MilliVolt" BMC
   SG_ CMC_04_CellVoltage_04 : 48|12@1+ (1,1000) [1000|5091] "MilliVolt" BMC

BO_ 445 CMC_04_02: 8 CMC_04
   SG_ CMC_04_02_CRC : 0|8@1+ (1,0) [0|255] "" BMC
   SG_ CMC_04_CellVoltage_05 : 12|12@1+ (1,1000) [1000|5091] "MilliVolt" BMC
   SG_ CMC_04_CellVoltage_06 : 24|12@1+ (1,1000) [1000|5091] "MilliVolt" BMC
   SG_ CMC_04_CellVoltage_07 : 36|12@1+ (1,1000) [1000|5091] "MilliVolt" BMC
   SG_ CMC_04_CellVoltage_08 : 48|12@1+ (1,1000) [1000|5091] "MilliVolt" BMC

BO_ 446 CMC_04_03: 8 CMC_04
   SG_ CMC_04_03_CRC : 0|8@1+ (1,0) [0|255] "" BMC
   SG_ CMC_04_CellVoltage_09 : 12|12@1+ (1,1000) [1000|5091] "MilliVolt" BMC
   SG_ CMC_04_CellVoltage_10 : 24|12@1+ (1,1000) [1000|5091] "MilliVolt" BMC
   SG_ CMC_04_CellVoltage_11 : 36|12@1+ (1,1000) [1000|5091] "MilliVolt" BMC
   SG_ CMC_04_CellVoltage_12 : 48|12@1+ (1,1000) [1000|5091] "MilliVolt" BMC

BO_ 476 P2_CMC_04_01: 8 Vector__XXX
   SG_ P2_CMC_04_01_CRC : 0|8@1+ (1,0) [0|255] "" BMC
   SG_ P2_CMC_04_CellVoltage_01 : 12|12@1+ (1,1000) [1000|5091] "MilliVolt" BMC
   SG_ P2_CMC_04_CellVoltage_02 : 24|12@1+ (1,1000) [1000|5091] "MilliVolt" BMC
   SG_ P2_CMC_04_CellVoltage_03 : 36|12@1+ (1,1000) [1000|5091] "MilliVolt" BMC
   SG_ P2_CMC_04_CellVoltage_04 : 48|12@1+ (1,1000) [1000|5091] "MilliVolt" BMC

BO_ 477 P2_CMC_04_02: 8 Vector__XXX
   SG_ P2_CMC_04_02_CRC : 0|8@1+ (1,0) [0|255] "" BMC
   SG_ P2_CMC_04_CellVoltage_05 : 12|12@1+ (1,1000) [1000|5091] "MilliVolt" BMC
   SG_ P2_CMC_04_CellVoltage_06 : 24|12@1+ (1,1000) [1000|5091] "MilliVolt" BMC
   SG_ P2_CMC_04_CellVoltage_07 : 36|12@1+ (1,1000) [1000|5091] "MilliVolt" BMC
   SG_ P2_CMC_04_CellVoltage_08 : 48|12@1+ (1,1000) [1000|5091] "MilliVolt" BMC

BO_ 478 P2_CMC_04_03: 8 Vector__XXX
   SG_ P2_CMC_04_03_CRC : 0|8@1+ (1,0) [0|255] "" BMC
   SG_ P2_CMC_04_CellVoltage_09 : 12|12@1+ (1,1000) [1000|5091] "MilliVolt" BMC
   SG_ P2_CMC_04_CellVoltage_10 : 24|12@1+ (1,1000) [1000|5091] "MilliVolt" BMC
   SG_ P2_CMC_04_CellVoltage_11 : 36|12@1+ (1,1000) [1000|5091] "MilliVolt" BMC
   SG_ P2_CMC_04_CellVoltage_12 : 48|12@1+ (1,1000) [1000|5091] "MilliVolt" BMC

BO_ 441799684 CMC_04_05: 8 CMC_04
   SG_ CMC_04_Temperature_1 : 0|8@1+ (0.5,-40) [-40|86] "DegreeCelcius" BMC
   SG_ CMC_04_Temperature_2 : 8|8@1+ (0.5,-40) [-40|86] "DegreeCelcius" BMC
   SG_ Cell01Balance : 16|1@1+ (1,0) [0|0] "" Vector__XXX
   SG_ Cell02Balance : 17|1@1+ (1,0) [0|0] "" Vector__XXX
   SG_ Cell03Balance : 18|1@1+ (1,0) [0|0] "" Vector__XXX
   SG_ Cell04Balance : 19|1@1+ (1,0) [0|0] "" Vector__XXX
   SG_ Cell05Balance : 20|1@1+ (1,0) [0|0] "" Vector__XXX
   SG_ Cell06Balance : 21|1@1+ (1,0) [0|0] "" Vector__XXX
   SG_ Cell07Balance : 22|1@1+ (1,0) [0|0] "" Vector__XXX
   SG_ Cell08Balance : 23|1@1+ (1,0) [0|0] "" Vector__XXX
   SG_ Cell09Balance : 24|1@1+ (1,0) [0|0] "" Vector__XXX
   SG_ Cell10Balance : 25|1@1+ (1,0) [0|0] "" Vector__XXX
   SG_ Cell11Balance : 26|1@1+ (1,0) [0|0] "" Vector__XXX
   SG_ Cell12Balance : 27|1@1+ (1,0) [0|0] "" Vector__XXX

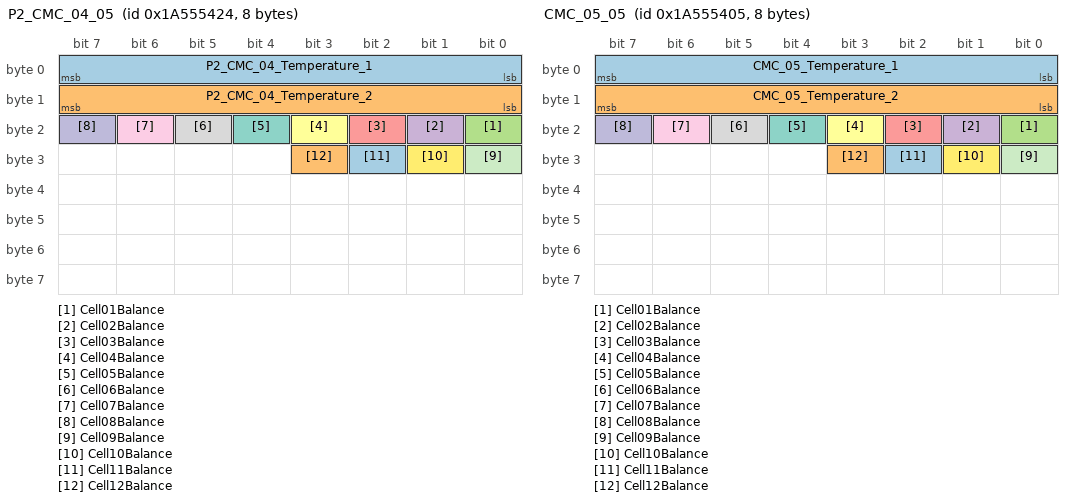
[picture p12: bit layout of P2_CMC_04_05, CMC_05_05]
BO_ 441799716 P2_CMC_04_05: 8 Vector__XXX
   SG_ P2_CMC_04_Temperature_1 : 0|8@1+ (0.5,-40) [-40|86] "DegreeCelcius" BMC
   SG_ P2_CMC_04_Temperature_2 : 8|8@1+ (0.5,-40) [-40|86] "DegreeCelcius" BMC
   SG_ Cell01Balance : 16|1@1+ (1,0) [0|0] "" Vector__XXX
   SG_ Cell02Balance : 17|1@1+ (1,0) [0|0] "" Vector__XXX
   SG_ Cell03Balance : 18|1@1+ (1,0) [0|0] "" Vector__XXX
   SG_ Cell04Balance : 19|1@1+ (1,0) [0|0] "" Vector__XXX
   SG_ Cell05Balance : 20|1@1+ (1,0) [0|0] "" Vector__XXX
   SG_ Cell06Balance : 21|1@1+ (1,0) [0|0] "" Vector__XXX
   SG_ Cell07Balance : 22|1@1+ (1,0) [0|0] "" Vector__XXX
   SG_ Cell08Balance : 23|1@1+ (1,0) [0|0] "" Vector__XXX
   SG_ Cell09Balance : 24|1@1+ (1,0) [0|0] "" Vector__XXX
   SG_ Cell10Balance : 25|1@1+ (1,0) [0|0] "" Vector__XXX
   SG_ Cell11Balance : 26|1@1+ (1,0) [0|0] "" Vector__XXX
   SG_ Cell12Balance : 27|1@1+ (1,0) [0|0] "" Vector__XXX

BO_ 448 CMC_05_01: 8 CMC_05
   SG_ CMC_05_01_CRC : 0|8@1+ (1,0) [0|255] "" BMC
   SG_ CMC_05_CellVoltage_01 : 12|12@1+ (1,1000) [1000|5091] "MilliVolt" BMC
   SG_ CMC_05_CellVoltage_02 : 24|12@1+ (1,1000) [1000|5091] "MilliVolt" BMC
   SG_ CMC_05_CellVoltage_03 : 36|12@1+ (1,1000) [1000|5091] "MilliVolt" BMC
   SG_ CMC_05_CellVoltage_04 : 48|12@1+ (1,1000) [1000|5091] "MilliVolt" BMC

BO_ 449 CMC_05_02: 8 CMC_05
   SG_ CMC_05_02_CRC : 0|8@1+ (1,0) [0|255] "" BMC
   SG_ CMC_05_CellVoltage_05 : 12|12@1+ (1,1000) [1000|5091] "MilliVolt" BMC
   SG_ CMC_05_CellVoltage_06 : 24|12@1+ (1,1000) [1000|5091] "MilliVolt" BMC
   SG_ CMC_05_CellVoltage_07 : 36|12@1+ (1,1000) [1000|5091] "MilliVolt" BMC
   SG_ CMC_05_CellVoltage_08 : 48|12@1+ (1,1000) [1000|5091] "MilliVolt" BMC

BO_ 450 CMC_05_03: 8 CMC_05
   SG_ CMC_05_03_CRC : 0|8@1+ (1,0) [0|255] "" BMC
   SG_ CMC_05_CellVoltage_09 : 12|12@1+ (1,1000) [1000|5091] "MilliVolt" BMC
   SG_ CMC_05_CellVoltage_10 : 24|12@1+ (1,1000) [1000|5091] "MilliVolt" BMC
   SG_ CMC_05_CellVoltage_11 : 36|12@1+ (1,1000) [1000|5091] "MilliVolt" BMC
   SG_ CMC_05_CellVoltage_12 : 48|12@1+ (1,1000) [1000|5091] "MilliVolt" BMC

BO_ 480 P2_CMC_05_01: 8 Vector__XXX
   SG_ P2_CMC_05_01_CRC : 0|8@1+ (1,0) [0|255] "" BMC
   SG_ P2_CMC_05_CellVoltage_01 : 12|12@1+ (1,1000) [1000|5091] "MilliVolt" BMC
   SG_ P2_CMC_05_CellVoltage_02 : 24|12@1+ (1,1000) [1000|5091] "MilliVolt" BMC
   SG_ P2_CMC_05_CellVoltage_03 : 36|12@1+ (1,1000) [1000|5091] "MilliVolt" BMC
   SG_ P2_CMC_05_CellVoltage_04 : 48|12@1+ (1,1000) [1000|5091] "MilliVolt" BMC

BO_ 481 P2_CMC_05_02: 8 Vector__XXX
   SG_ P2_CMC_05_02_CRC : 0|8@1+ (1,0) [0|255] "" BMC
   SG_ P2_CMC_05_CellVoltage_05 : 12|12@1+ (1,1000) [1000|5091] "MilliVolt" BMC
   SG_ P2_CMC_05_CellVoltage_06 : 24|12@1+ (1,1000) [1000|5091] "MilliVolt" BMC
   SG_ P2_CMC_05_CellVoltage_07 : 36|12@1+ (1,1000) [1000|5091] "MilliVolt" BMC
   SG_ P2_CMC_05_CellVoltage_08 : 48|12@1+ (1,1000) [1000|5091] "MilliVolt" BMC

BO_ 482 P2_CMC_05_03: 8 Vector__XXX
   SG_ P2_CMC_05_03_CRC : 0|8@1+ (1,0) [0|255] "" BMC
   SG_ P2_CMC_05_CellVoltage_09 : 12|12@1+ (1,1000) [1000|5091] "MilliVolt" BMC
   SG_ P2_CMC_05_CellVoltage_10 : 24|12@1+ (1,1000) [1000|5091] "MilliVolt" BMC
   SG_ P2_CMC_05_CellVoltage_11 : 36|12@1+ (1,1000) [1000|5091] "MilliVolt" BMC
   SG_ P2_CMC_05_CellVoltage_12 : 48|12@1+ (1,1000) [1000|5091] "MilliVolt" BMC

BO_ 441799685 CMC_05_05: 8 CMC_05
   SG_ CMC_05_Temperature_1 : 0|8@1+ (0.5,-40) [-40|86] "DegreeCelcius" BMC
   SG_ CMC_05_Temperature_2 : 8|8@1+ (0.5,-40) [-40|86] "DegreeCelcius" BMC
   SG_ Cell01Balance : 16|1@1+ (1,0) [0|0] "" Vector__XXX
   SG_ Cell02Balance : 17|1@1+ (1,0) [0|0] "" Vector__XXX
   SG_ Cell03Balance : 18|1@1+ (1,0) [0|0] "" Vector__XXX
   SG_ Cell04Balance : 19|1@1+ (1,0) [0|0] "" Vector__XXX
   SG_ Cell05Balance : 20|1@1+ (1,0) [0|0] "" Vector__XXX
   SG_ Cell06Balance : 21|1@1+ (1,0) [0|0] "" Vector__XXX
   SG_ Cell07Balance : 22|1@1+ (1,0) [0|0] "" Vector__XXX
   SG_ Cell08Balance : 23|1@1+ (1,0) [0|0] "" Vector__XXX
   SG_ Cell09Balance : 24|1@1+ (1,0) [0|0] "" Vector__XXX
   SG_ Cell10Balance : 25|1@1+ (1,0) [0|0] "" Vector__XXX
   SG_ Cell11Balance : 26|1@1+ (1,0) [0|0] "" Vector__XXX
   SG_ Cell12Balance : 27|1@1+ (1,0) [0|0] "" Vector__XXX

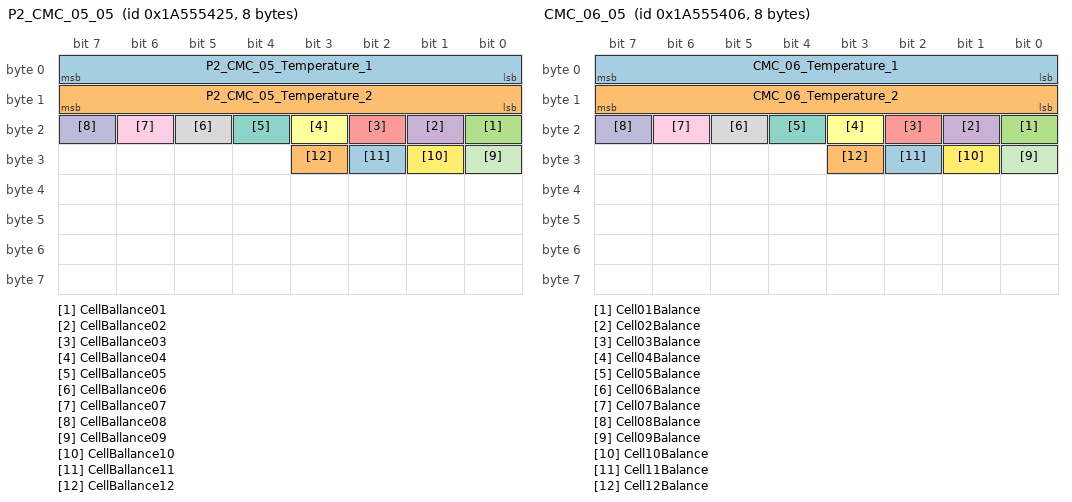
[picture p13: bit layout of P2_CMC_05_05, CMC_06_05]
BO_ 441799717 P2_CMC_05_05: 8 Vector__XXX
   SG_ P2_CMC_05_Temperature_1 : 0|8@1+ (0.5,-40) [-40|86] "DegreeCelcius" BMC
   SG_ P2_CMC_05_Temperature_2 : 8|8@1+ (0.5,-40) [-40|86] "DegreeCelcius" BMC
   SG_ CellBallance01 : 16|1@1+ (1,0) [0|0] "" Vector__XXX
   SG_ CellBallance02 : 17|1@1+ (1,0) [0|0] "" Vector__XXX
   SG_ CellBallance03 : 18|1@1+ (1,0) [0|0] "" Vector__XXX
   SG_ CellBallance04 : 19|1@1+ (1,0) [0|0] "" Vector__XXX
   SG_ CellBallance05 : 20|1@1+ (1,0) [0|0] "" Vector__XXX
   SG_ CellBallance06 : 21|1@1+ (1,0) [0|0] "" Vector__XXX
   SG_ CellBallance07 : 22|1@1+ (1,0) [0|0] "" Vector__XXX
   SG_ CellBallance08 : 23|1@1+ (1,0) [0|0] "" Vector__XXX
   SG_ CellBallance09 : 24|1@1+ (1,0) [0|0] "" Vector__XXX
   SG_ CellBallance10 : 25|1@1+ (1,0) [0|0] "" Vector__XXX
   SG_ CellBallance11 : 26|1@1+ (1,0) [0|0] "" Vector__XXX
   SG_ CellBallance12 : 27|1@1+ (1,0) [0|0] "" Vector__XXX

BO_ 452 CMC_06_01: 8 CMC_06
   SG_ CMC_06_01_CRC : 0|8@1+ (1,0) [0|255] "" BMC
   SG_ CMC_06_CellVoltage_01 : 12|12@1+ (1,1000) [1000|5091] "MilliVolt" BMC
   SG_ CMC_06_CellVoltage_02 : 24|12@1+ (1,1000) [1000|5091] "MilliVolt" BMC
   SG_ CMC_06_CellVoltage_03 : 36|12@1+ (1,1000) [1000|5091] "MilliVolt" BMC
   SG_ CMC_06_CellVoltage_04 : 48|12@1+ (1,1000) [1000|5091] "MilliVolt" BMC

BO_ 453 CMC_06_02: 8 CMC_06
   SG_ CMC_06_02_CRC : 0|8@1+ (1,0) [0|255] "" BMC
   SG_ CMC_06_CellVoltage_05 : 12|12@1+ (1,1000) [1000|5091] "MilliVolt" BMC
   SG_ CMC_06_CellVoltage_06 : 24|12@1+ (1,1000) [1000|5091] "MilliVolt" BMC
   SG_ CMC_06_CellVoltage_07 : 36|12@1+ (1,1000) [1000|5091] "MilliVolt" BMC
   SG_ CMC_06_CellVoltage_08 : 48|12@1+ (1,1000) [1000|5091] "MilliVolt" BMC

BO_ 454 CMC_06_03: 8 CMC_06
   SG_ CMC_06_03_CRC : 0|8@1+ (1,0) [0|255] "" BMC
   SG_ CMC_06_CellVoltage_09 : 12|12@1+ (1,1000) [1000|5091] "MilliVolt" BMC
   SG_ CMC_06_CellVoltage_10 : 24|12@1+ (1,1000) [1000|5091] "MilliVolt" BMC
   SG_ CMC_06_CellVoltage_11 : 36|12@1+ (1,1000) [1000|5091] "MilliVolt" BMC
   SG_ CMC_06_CellVoltage_12 : 48|12@1+ (1,1000) [1000|5091] "MilliVolt" BMC

BO_ 484 P2_CMC_06_01: 8 Vector__XXX
   SG_ P2_CMC_06_01_CRC : 0|8@1+ (1,0) [0|255] "" BMC
   SG_ P2_CMC_06_CellVoltage_01 : 12|12@1+ (1,1000) [1000|5091] "MilliVolt" BMC
   SG_ P2_CMC_06_CellVoltage_02 : 24|12@1+ (1,1000) [1000|5091] "MilliVolt" BMC
   SG_ P2_CMC_06_CellVoltage_03 : 36|12@1+ (1,1000) [1000|5091] "MilliVolt" BMC
   SG_ P2_CMC_06_CellVoltage_04 : 48|12@1+ (1,1000) [1000|5091] "MilliVolt" BMC

BO_ 485 P2_CMC_06_02: 8 Vector__XXX
   SG_ P2_CMC_06_02_CRC : 0|8@1+ (1,0) [0|255] "" BMC
   SG_ P2_CMC_06_CellVoltage_05 : 12|12@1+ (1,1000) [1000|5091] "MilliVolt" BMC
   SG_ P2_CMC_06_CellVoltage_06 : 24|12@1+ (1,1000) [1000|5091] "MilliVolt" BMC
   SG_ P2_CMC_06_CellVoltage_07 : 36|12@1+ (1,1000) [1000|5091] "MilliVolt" BMC
   SG_ P2_CMC_06_CellVoltage_08 : 48|12@1+ (1,1000) [1000|5091] "MilliVolt" BMC

BO_ 486 P2_CMC_06_03: 8 Vector__XXX
   SG_ P2_CMC_06_03_CRC : 0|8@1+ (1,0) [0|255] "" BMC
   SG_ P2_CMC_06_CellVoltage_09 : 12|12@1+ (1,1000) [1000|5091] "MilliVolt" BMC
   SG_ P2_CMC_06_CellVoltage_10 : 24|12@1+ (1,1000) [1000|5091] "MilliVolt" BMC
   SG_ P2_CMC_06_CellVoltage_11 : 36|12@1+ (1,1000) [1000|5091] "MilliVolt" BMC
   SG_ P2_CMC_06_CellVoltage_12 : 48|12@1+ (1,1000) [1000|5091] "MilliVolt" BMC

BO_ 441799686 CMC_06_05: 8 CMC_06
   SG_ CMC_06_Temperature_1 : 0|8@1+ (0.5,-40) [-40|86] "DegreeCelcius" BMC
   SG_ CMC_06_Temperature_2 : 8|8@1+ (0.5,-40) [-40|86] "DegreeCelcius" BMC
   SG_ Cell01Balance : 16|1@1+ (1,0) [0|0] "" Vector__XXX
   SG_ Cell02Balance : 17|1@1+ (1,0) [0|0] "" Vector__XXX
   SG_ Cell03Balance : 18|1@1+ (1,0) [0|0] "" Vector__XXX
   SG_ Cell04Balance : 19|1@1+ (1,0) [0|0] "" Vector__XXX
   SG_ Cell05Balance : 20|1@1+ (1,0) [0|0] "" Vector__XXX
   SG_ Cell06Balance : 21|1@1+ (1,0) [0|0] "" Vector__XXX
   SG_ Cell07Balance : 22|1@1+ (1,0) [0|0] "" Vector__XXX
   SG_ Cell08Balance : 23|1@1+ (1,0) [0|0] "" Vector__XXX
   SG_ Cell09Balance : 24|1@1+ (1,0) [0|0] "" Vector__XXX
   SG_ Cell10Balance : 25|1@1+ (1,0) [0|0] "" Vector__XXX
   SG_ Cell11Balance : 26|1@1+ (1,0) [0|0] "" Vector__XXX
   SG_ Cell12Balance : 27|1@1+ (1,0) [0|0] "" Vector__XXX

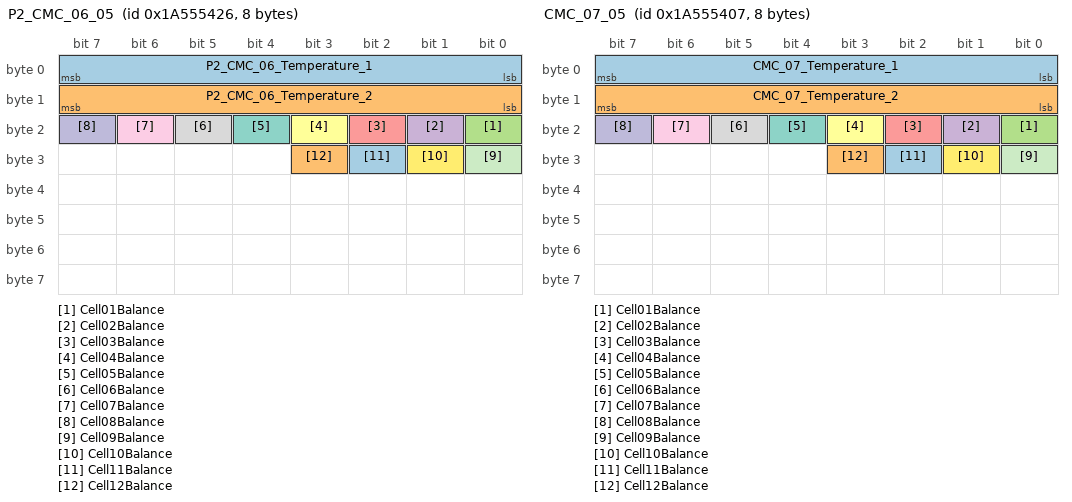
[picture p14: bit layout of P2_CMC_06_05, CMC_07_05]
BO_ 441799718 P2_CMC_06_05: 8 Vector__XXX
   SG_ P2_CMC_06_Temperature_1 : 0|8@1+ (0.5,-40) [-40|86] "DegreeCelcius" BMC
   SG_ P2_CMC_06_Temperature_2 : 8|8@1+ (0.5,-40) [-40|86] "DegreeCelcius" BMC
   SG_ Cell01Balance : 16|1@1+ (1,0) [0|0] "" Vector__XXX
   SG_ Cell02Balance : 17|1@1+ (1,0) [0|0] "" Vector__XXX
   SG_ Cell03Balance : 18|1@1+ (1,0) [0|0] "" Vector__XXX
   SG_ Cell04Balance : 19|1@1+ (1,0) [0|0] "" Vector__XXX
   SG_ Cell05Balance : 20|1@1+ (1,0) [0|0] "" Vector__XXX
   SG_ Cell06Balance : 21|1@1+ (1,0) [0|0] "" Vector__XXX
   SG_ Cell07Balance : 22|1@1+ (1,0) [0|0] "" Vector__XXX
   SG_ Cell08Balance : 23|1@1+ (1,0) [0|0] "" Vector__XXX
   SG_ Cell09Balance : 24|1@1+ (1,0) [0|0] "" Vector__XXX
   SG_ Cell10Balance : 25|1@1+ (1,0) [0|0] "" Vector__XXX
   SG_ Cell11Balance : 26|1@1+ (1,0) [0|0] "" Vector__XXX
   SG_ Cell12Balance : 27|1@1+ (1,0) [0|0] "" Vector__XXX

BO_ 456 CMC_07_01: 8 CMC_07
   SG_ CMC_07_01_CRC : 0|8@1+ (1,0) [0|255] "" BMC
   SG_ CMC_07_CellVoltage_01 : 12|12@1+ (1,1000) [1000|5091] "MilliVolt" BMC
   SG_ CMC_07_CellVoltage_02 : 24|12@1+ (1,1000) [1000|5091] "MilliVolt" BMC
   SG_ CMC_07_CellVoltage_03 : 36|12@1+ (1,1000) [1000|5091] "MilliVolt" BMC
   SG_ CMC_07_CellVoltage_04 : 48|12@1+ (1,1000) [1000|5091] "MilliVolt" BMC

BO_ 457 CMC_07_02: 8 CMC_07
   SG_ CMC_07_02_CRC : 0|8@1+ (1,0) [0|255] "" BMC
   SG_ CMC_07_CellVoltage_05 : 12|12@1+ (1,1000) [1000|5091] "MilliVolt" BMC
   SG_ CMC_07_CellVoltage_06 : 24|12@1+ (1,1000) [1000|5091] "MilliVolt" BMC
   SG_ CMC_07_CellVoltage_07 : 36|12@1+ (1,1000) [1000|5091] "MilliVolt" BMC
   SG_ CMC_07_CellVoltage_08 : 48|12@1+ (1,1000) [1000|5091] "MilliVolt" BMC

BO_ 458 CMC_07_03: 8 CMC_07
   SG_ CMC_07_03_CRC : 0|8@1+ (1,0) [0|255] "" BMC
   SG_ CMC_07_CellVoltage_09 : 12|12@1+ (1,1000) [1000|5091] "MilliVolt" BMC
   SG_ CMC_07_CellVoltage_10 : 24|12@1+ (1,1000) [1000|5091] "MilliVolt" BMC
   SG_ CMC_07_CellVoltage_11 : 36|12@1+ (1,1000) [1000|5091] "MilliVolt" BMC
   SG_ CMC_07_CellVoltage_12 : 48|12@1+ (1,1000) [1000|5091] "MilliVolt" BMC

BO_ 488 P2_CMC_07_01: 8 Vector__XXX
   SG_ P2_CMC_07_01_CRC : 0|8@1+ (1,0) [0|255] "" BMC
   SG_ P2_CMC_07_CellVoltage_01 : 12|12@1+ (1,1000) [1000|5091] "MilliVolt" BMC
   SG_ P2_CMC_07_CellVoltage_02 : 24|12@1+ (1,1000) [1000|5091] "MilliVolt" BMC
   SG_ P2_CMC_07_CellVoltage_03 : 36|12@1+ (1,1000) [1000|5091] "MilliVolt" BMC
   SG_ P2_CMC_07_CellVoltage_04 : 48|12@1+ (1,1000) [1000|5091] "MilliVolt" BMC

BO_ 489 P2_CMC_07_02: 8 Vector__XXX
   SG_ P2_CMC_07_02_CRC : 0|8@1+ (1,0) [0|255] "" BMC
   SG_ P2_CMC_07_CellVoltage_05 : 12|12@1+ (1,1000) [1000|5091] "MilliVolt" BMC
   SG_ P2_CMC_07_CellVoltage_06 : 24|12@1+ (1,1000) [1000|5091] "MilliVolt" BMC
   SG_ P2_CMC_07_CellVoltage_07 : 36|12@1+ (1,1000) [1000|5091] "MilliVolt" BMC
   SG_ P2_CMC_07_CellVoltage_08 : 48|12@1+ (1,1000) [1000|5091] "MilliVolt" BMC

BO_ 490 P2_CMC_07_03: 8 Vector__XXX
   SG_ P2_CMC_07_03_CRC : 0|8@1+ (1,0) [0|255] "" BMC
   SG_ P2_CMC_07_CellVoltage_09 : 12|12@1+ (1,1000) [1000|5091] "MilliVolt" BMC
   SG_ P2_CMC_07_CellVoltage_10 : 24|12@1+ (1,1000) [1000|5091] "MilliVolt" BMC
   SG_ P2_CMC_07_CellVoltage_11 : 36|12@1+ (1,1000) [1000|5091] "MilliVolt" BMC
   SG_ P2_CMC_07_CellVoltage_12 : 48|12@1+ (1,1000) [1000|5091] "MilliVolt" BMC

BO_ 441799687 CMC_07_05: 8 CMC_07
   SG_ CMC_07_Temperature_1 : 0|8@1+ (0.5,-40) [-40|86] "DegreeCelcius" BMC
   SG_ CMC_07_Temperature_2 : 8|8@1+ (0.5,-40) [-40|86] "DegreeCelcius" BMC
   SG_ Cell01Balance : 16|1@1+ (1,0) [0|0] "" Vector__XXX
   SG_ Cell02Balance : 17|1@1+ (1,0) [0|0] "" Vector__XXX
   SG_ Cell03Balance : 18|1@1+ (1,0) [0|0] "" Vector__XXX
   SG_ Cell04Balance : 19|1@1+ (1,0) [0|0] "" Vector__XXX
   SG_ Cell05Balance : 20|1@1+ (1,0) [0|0] "" Vector__XXX
   SG_ Cell06Balance : 21|1@1+ (1,0) [0|0] "" Vector__XXX
   SG_ Cell07Balance : 22|1@1+ (1,0) [0|0] "" Vector__XXX
   SG_ Cell08Balance : 23|1@1+ (1,0) [0|0] "" Vector__XXX
   SG_ Cell09Balance : 24|1@1+ (1,0) [0|0] "" Vector__XXX
   SG_ Cell10Balance : 25|1@1+ (1,0) [0|0] "" Vector__XXX
   SG_ Cell11Balance : 26|1@1+ (1,0) [0|0] "" Vector__XXX
   SG_ Cell12Balance : 27|1@1+ (1,0) [0|0] "" Vector__XXX

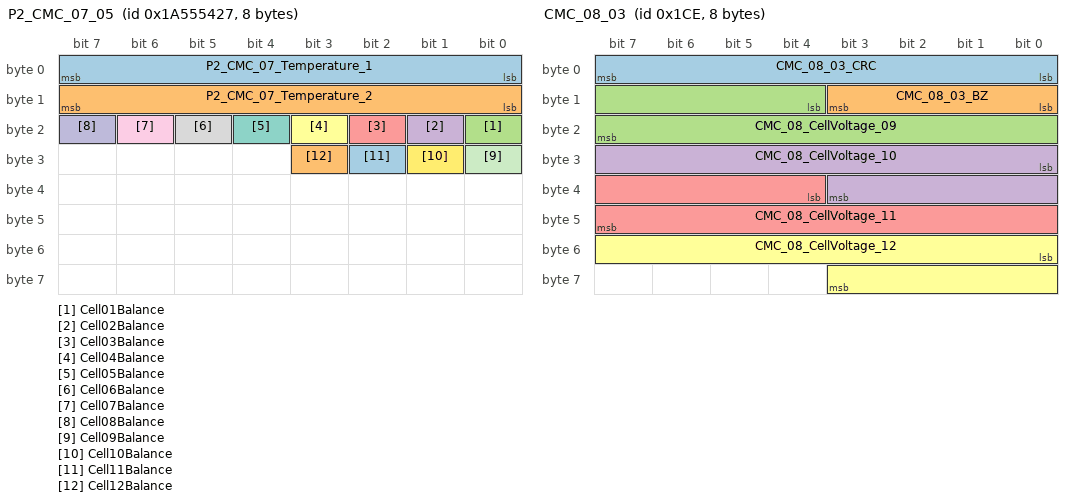
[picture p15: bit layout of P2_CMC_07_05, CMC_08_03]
BO_ 441799719 P2_CMC_07_05: 8 Vector__XXX
   SG_ P2_CMC_07_Temperature_1 : 0|8@1+ (0.5,-40) [-40|86] "DegreeCelcius" BMC
   SG_ P2_CMC_07_Temperature_2 : 8|8@1+ (0.5,-40) [-40|86] "DegreeCelcius" BMC
   SG_ Cell01Balance : 16|1@1+ (1,0) [0|0] "" Vector__XXX
   SG_ Cell02Balance : 17|1@1+ (1,0) [0|0] "" Vector__XXX
   SG_ Cell03Balance : 18|1@1+ (1,0) [0|0] "" Vector__XXX
   SG_ Cell04Balance : 19|1@1+ (1,0) [0|0] "" Vector__XXX
   SG_ Cell05Balance : 20|1@1+ (1,0) [0|0] "" Vector__XXX
   SG_ Cell06Balance : 21|1@1+ (1,0) [0|0] "" Vector__XXX
   SG_ Cell07Balance : 22|1@1+ (1,0) [0|0] "" Vector__XXX
   SG_ Cell08Balance : 23|1@1+ (1,0) [0|0] "" Vector__XXX
   SG_ Cell09Balance : 24|1@1+ (1,0) [0|0] "" Vector__XXX
   SG_ Cell10Balance : 25|1@1+ (1,0) [0|0] "" Vector__XXX
   SG_ Cell11Balance : 26|1@1+ (1,0) [0|0] "" Vector__XXX
   SG_ Cell12Balance : 27|1@1+ (1,0) [0|0] "" Vector__XXX

BO_ 460 CMC_08_01: 8 CMC_08
   SG_ CMC_08_01_CRC : 0|8@1+ (1,0) [0|255] "" BMC
   SG_ CMC_08_CellVoltage_01 : 12|12@1+ (1,1000) [1000|5091] "MilliVolt" BMC
   SG_ CMC_08_CellVoltage_02 : 24|12@1+ (1,1000) [1000|5091] "MilliVolt" BMC
   SG_ CMC_08_CellVoltage_03 : 36|12@1+ (1,1000) [1000|5091] "MilliVolt" BMC
   SG_ CMC_08_CellVoltage_04 : 48|12@1+ (1,1000) [1000|5091] "MilliVolt" BMC

BO_ 461 CMC_08_02: 8 CMC_08
   SG_ CMC_08_02_CRC : 0|8@1+ (1,0) [0|255] "" BMC
   SG_ CMC_08_CellVoltage_05 : 12|12@1+ (1,1000) [1000|5091] "MilliVolt" BMC
   SG_ CMC_08_CellVoltage_06 : 24|12@1+ (1,1000) [1000|5091] "MilliVolt" BMC
   SG_ CMC_08_CellVoltage_07 : 36|12@1+ (1,1000) [1000|5091] "MilliVolt" BMC
   SG_ CMC_08_CellVoltage_08 : 48|12@1+ (1,1000) [1000|5091] "MilliVolt" BMC

BO_ 462 CMC_08_03: 8 CMC_08
   SG_ CMC_08_03_CRC : 0|8@1+ (1,0) [0|255] "" BMC
   SG_ CMC_08_03_BZ : 8|4@1+ (1,0) [0|15] "" BMC
   SG_ CMC_08_CellVoltage_09 : 12|12@1+ (1,1000) [1000|5091] "MilliVolt" BMC
   SG_ CMC_08_CellVoltage_10 : 24|12@1+ (1,1000) [1000|5091] "MilliVolt" BMC
   SG_ CMC_08_CellVoltage_11 : 36|12@1+ (1,1000) [1000|5091] "MilliVolt" BMC
   SG_ CMC_08_CellVoltage_12 : 48|12@1+ (1,1000) [1000|5091] "MilliVolt" BMC

BO_ 492 P2_CMC_08_01: 8 Vector__XXX
   SG_ P2_CMC_08_01_CRC : 0|8@1+ (1,0) [0|255] "" BMC
   SG_ P2_CMC_08_CellVoltage_01 : 12|12@1+ (1,1000) [1000|5091] "MilliVolt" BMC
   SG_ P2_CMC_08_CellVoltage_02 : 24|12@1+ (1,1000) [1000|5091] "MilliVolt" BMC
   SG_ P2_CMC_08_CellVoltage_03 : 36|12@1+ (1,1000) [1000|5091] "MilliVolt" BMC
   SG_ P2_CMC_08_CellVoltage_04 : 48|12@1+ (1,1000) [1000|5091] "MilliVolt" BMC

BO_ 493 P2_CMC_08_02: 8 Vector__XXX
   SG_ P2_CMC_08_02_CRC : 0|8@1+ (1,0) [0|255] "" BMC
   SG_ P2_CMC_08_CellVoltage_05 : 12|12@1+ (1,1000) [1000|5091] "MilliVolt" BMC
   SG_ P2_CMC_08_CellVoltage_06 : 24|12@1+ (1,1000) [1000|5091] "MilliVolt" BMC
   SG_ P2_CMC_08_CellVoltage_07 : 36|12@1+ (1,1000) [1000|5091] "MilliVolt" BMC
   SG_ P2_CMC_08_CellVoltage_08 : 48|12@1+ (1,1000) [1000|5091] "MilliVolt" BMC

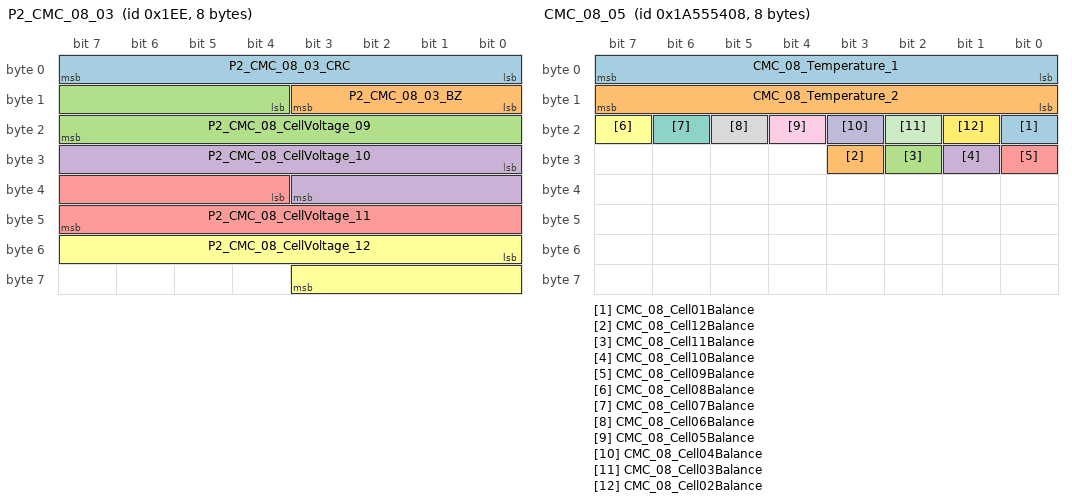
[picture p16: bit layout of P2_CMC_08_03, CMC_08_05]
BO_ 494 P2_CMC_08_03: 8 CMC_08
   SG_ P2_CMC_08_03_CRC : 0|8@1+ (1,0) [0|255] "" BMC
   SG_ P2_CMC_08_03_BZ : 8|4@1+ (1,0) [0|15] "" BMC
   SG_ P2_CMC_08_CellVoltage_09 : 12|12@1+ (1,1000) [1000|5091] "MilliVolt" BMC
   SG_ P2_CMC_08_CellVoltage_10 : 24|12@1+ (1,1000) [1000|5091] "MilliVolt" BMC
   SG_ P2_CMC_08_CellVoltage_11 : 36|12@1+ (1,1000) [1000|5091] "MilliVolt" BMC
   SG_ P2_CMC_08_CellVoltage_12 : 48|12@1+ (1,1000) [1000|5091] "MilliVolt" BMC

BO_ 441799688 CMC_08_05: 8 CMC_08
   SG_ CMC_08_Cell01Balance : 16|1@1+ (1,0) [0|1] "" Vector__XXX
   SG_ CMC_08_Cell12Balance : 27|1@1+ (1,0) [0|1] "" Vector__XXX
   SG_ CMC_08_Cell11Balance : 26|1@1+ (1,0) [0|1] "" Vector__XXX
   SG_ CMC_08_Cell10Balance : 25|1@1+ (1,0) [0|1] "" Vector__XXX
   SG_ CMC_08_Cell09Balance : 24|1@1+ (1,0) [0|1] "" Vector__XXX
   SG_ CMC_08_Cell08Balance : 23|1@1+ (1,0) [0|1] "" Vector__XXX
   SG_ CMC_08_Cell07Balance : 22|1@1+ (1,0) [0|1] "" Vector__XXX
   SG_ CMC_08_Cell06Balance : 21|1@1+ (1,0) [0|1] "" Vector__XXX
   SG_ CMC_08_Cell05Balance : 20|1@1+ (1,0) [0|1] "" Vector__XXX
   SG_ CMC_08_Cell04Balance : 19|1@1+ (1,0) [0|1] "" Vector__XXX
   SG_ CMC_08_Cell03Balance : 18|1@1+ (1,0) [0|1] "" Vector__XXX
   SG_ CMC_08_Cell02Balance : 17|1@1+ (1,0) [0|1] "" Vector__XXX
   SG_ CMC_08_Temperature_1 : 0|8@1+ (0.5,-40) [-40|86] "DegreeCelcius" BMC
   SG_ CMC_08_Temperature_2 : 8|8@1+ (0.5,-40) [-40|86] "DegreeCelcius" BMC

BO_ 151 Monitoring: 0 HVBatteryController
   SG_ ISO_MEAS_ACTI : 40|1@1+ (1,0) [0|0] "" Vector__XXX
   SG_ STATUS_SERVICE_DISCONNET : 60|1@1+ (1,0) [0|0] "" Vector__XXX
   SG_ ERROR_ISOLATION : 56|1@1+ (1,0) [0|0] "" Vector__XXX
   SG_ ERROR_CRASH : 49|1@1+ (1,0) [0|0] "" Vector__XXX
   SG_ ERROR_PILOT : 48|1@1+ (1,0) [0|0] "" Vector__XXX
   SG_ HV_SHUTOFF : 52|1@1+ (1,0) [0|0] "" Vector__XXX
   SG_ BMS_HV_STATUS : 61|2@1+ (1,0) [0|0] "" Vector__XXX
   SG_ CRC : 0|8@1+ (1,0) [0|0] "" Vector__XXX
   SG_ is_electricity : 12|12@1+ (1,0) [0|0] "" Vector__XXX

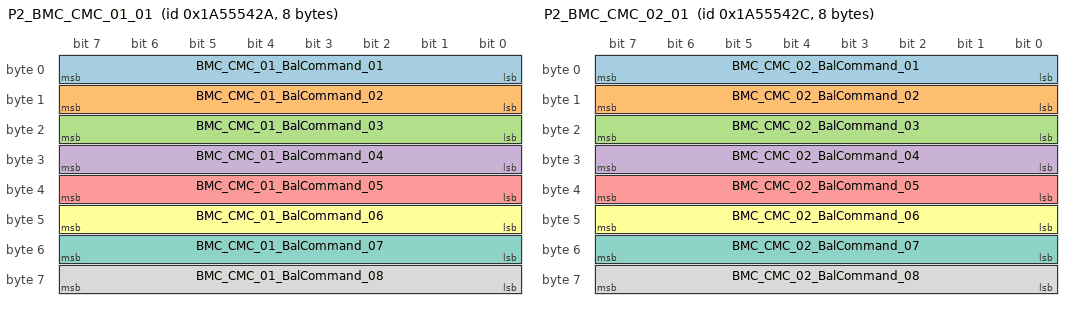
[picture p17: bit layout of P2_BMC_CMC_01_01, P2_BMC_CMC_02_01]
BO_ 441799722 P2_BMC_CMC_01_01: 8 BMC
   SG_ BMC_CMC_01_BalCommand_01 : 0|8@1+ (1,0) [0|0] "" Vector__XXX
   SG_ BMC_CMC_01_BalCommand_02 : 8|8@1+ (1,0) [0|0] "" Vector__XXX
   SG_ BMC_CMC_01_BalCommand_03 : 16|8@1+ (1,0) [0|0] "" Vector__XXX
   SG_ BMC_CMC_01_BalCommand_04 : 24|8@1+ (1,0) [0|0] "" Vector__XXX
   SG_ BMC_CMC_01_BalCommand_05 : 32|8@1+ (1,0) [0|0] "" Vector__XXX
   SG_ BMC_CMC_01_BalCommand_06 : 40|8@1+ (1,0) [0|0] "" Vector__XXX
   SG_ BMC_CMC_01_BalCommand_07 : 48|8@1+ (1,0) [0|0] "" Vector__XXX
   SG_ BMC_CMC_01_BalCommand_08 : 56|8@1+ (1,0) [0|0] "" Vector__XXX

BO_ 441799723 P2_BMC_CMC_01_02: 8 BMC
   SG_ BMC_CMC_01_BalCommand_09 : 0|8@1+ (1,0) [0|0] "" Vector__XXX
   SG_ BMC_CMC_01_BalCommand_10 : 8|8@1+ (1,0) [0|0] "" Vector__XXX
   SG_ BMC_CMC_01_BalCommand_11 : 16|8@1+ (1,0) [0|0] "" Vector__XXX
   SG_ BMC_CMC_01_BalCommand_12 : 24|8@1+ (1,0) [0|0] "" Vector__XXX

BO_ 441799724 P2_BMC_CMC_02_01: 8 BMC
   SG_ BMC_CMC_02_BalCommand_01 : 0|8@1+ (1,0) [0|0] "" Vector__XXX
   SG_ BMC_CMC_02_BalCommand_02 : 8|8@1+ (1,0) [0|0] "" Vector__XXX
   SG_ BMC_CMC_02_BalCommand_03 : 16|8@1+ (1,0) [0|0] "" Vector__XXX
   SG_ BMC_CMC_02_BalCommand_04 : 24|8@1+ (1,0) [0|0] "" Vector__XXX
   SG_ BMC_CMC_02_BalCommand_05 : 32|8@1+ (1,0) [0|0] "" Vector__XXX
   SG_ BMC_CMC_02_BalCommand_06 : 40|8@1+ (1,0) [0|0] "" Vector__XXX
   SG_ BMC_CMC_02_BalCommand_07 : 48|8@1+ (1,0) [0|0] "" Vector__XXX
   SG_ BMC_CMC_02_BalCommand_08 : 56|8@1+ (1,0) [0|0] "" Vector__XXX

BO_ 441799725 P2_BMC_CMC_02_02: 8 BMC
   SG_ BMC_CMC_02_BalCommand_09 : 0|8@1+ (1,0) [0|0] "" Vector__XXX
   SG_ BMC_CMC_02_BalCommand_10 : 8|8@1+ (1,0) [0|0] "" Vector__XXX
   SG_ BMC_CMC_02_BalCommand_11 : 16|8@1+ (1,0) [0|0] "" Vector__XXX
   SG_ BMC_CMC_02_BalCommand_12 : 24|8@1+ (1,0) [0|0] "" Vector__XXX

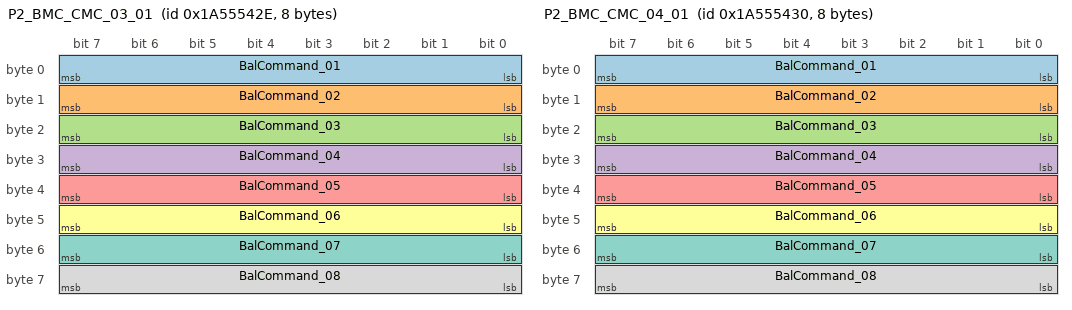
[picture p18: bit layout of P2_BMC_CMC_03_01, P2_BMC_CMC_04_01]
BO_ 441799726 P2_BMC_CMC_03_01: 8 BMC
   SG_ BalCommand_01 : 0|8@1+ (1,0) [0|0] "" Vector__XXX
   SG_ BalCommand_02 : 8|8@1+ (1,0) [0|0] "" Vector__XXX
   SG_ BalCommand_03 : 16|8@1+ (1,0) [0|0] "" Vector__XXX
   SG_ BalCommand_04 : 24|8@1+ (1,0) [0|0] "" Vector__XXX
   SG_ BalCommand_05 : 32|8@1+ (1,0) [0|0] "" Vector__XXX
   SG_ BalCommand_06 : 40|8@1+ (1,0) [0|0] "" Vector__XXX
   SG_ BalCommand_07 : 48|8@1+ (1,0) [0|0] "" Vector__XXX
   SG_ BalCommand_08 : 56|8@1+ (1,0) [0|0] "" Vector__XXX

BO_ 441799727 P2_BMC_CMC_03_02: 8 BMC
   SG_ BalCommand_09 : 0|8@1+ (1,0) [0|0] "" Vector__XXX
   SG_ BalCommand_10 : 8|8@1+ (1,0) [0|0] "" Vector__XXX
   SG_ BalCommand_11 : 16|8@1+ (1,0) [0|0] "" Vector__XXX
   SG_ BalCommand_12 : 24|8@1+ (1,0) [0|0] "" Vector__XXX

BO_ 441799728 P2_BMC_CMC_04_01: 8 BMC
   SG_ BalCommand_01 : 0|8@1+ (1,0) [0|0] "" Vector__XXX
   SG_ BalCommand_02 : 8|8@1+ (1,0) [0|0] "" Vector__XXX
   SG_ BalCommand_03 : 16|8@1+ (1,0) [0|0] "" Vector__XXX
   SG_ BalCommand_04 : 24|8@1+ (1,0) [0|0] "" Vector__XXX
   SG_ BalCommand_05 : 32|8@1+ (1,0) [0|0] "" Vector__XXX
   SG_ BalCommand_06 : 40|8@1+ (1,0) [0|0] "" Vector__XXX
   SG_ BalCommand_07 : 48|8@1+ (1,0) [0|0] "" Vector__XXX
   SG_ BalCommand_08 : 56|8@1+ (1,0) [0|0] "" Vector__XXX

BO_ 441799729 P2_BMC_CMC_04_02: 8 BMC
   SG_ BalCommand_09 : 0|8@1+ (1,0) [0|0] "" Vector__XXX
   SG_ BalCommand_10 : 8|8@1+ (1,0) [0|0] "" Vector__XXX
   SG_ BalCommand_11 : 16|8@1+ (1,0) [0|0] "" Vector__XXX
   SG_ BalCommand_12 : 24|8@1+ (1,0) [0|0] "" Vector__XXX

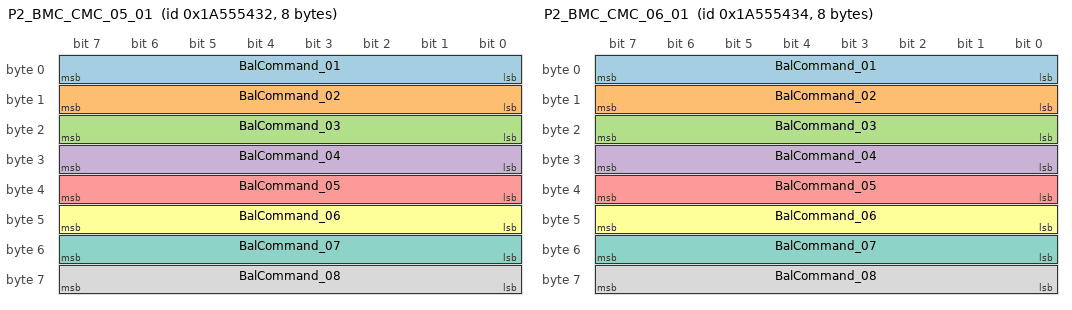
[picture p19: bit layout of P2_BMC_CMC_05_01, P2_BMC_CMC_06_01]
BO_ 441799730 P2_BMC_CMC_05_01: 8 BMC
   SG_ BalCommand_01 : 0|8@1+ (1,0) [0|0] "" Vector__XXX
   SG_ BalCommand_02 : 8|8@1+ (1,0) [0|0] "" Vector__XXX
   SG_ BalCommand_03 : 16|8@1+ (1,0) [0|0] "" Vector__XXX
   SG_ BalCommand_04 : 24|8@1+ (1,0) [0|0] "" Vector__XXX
   SG_ BalCommand_05 : 32|8@1+ (1,0) [0|0] "" Vector__XXX
   SG_ BalCommand_06 : 40|8@1+ (1,0) [0|0] "" Vector__XXX
   SG_ BalCommand_07 : 48|8@1+ (1,0) [0|0] "" Vector__XXX
   SG_ BalCommand_08 : 56|8@1+ (1,0) [0|0] "" Vector__XXX

BO_ 441799731 P2_BMC_CMC_05_02: 8 BMC
   SG_ BalCommand_09 : 0|8@1+ (1,0) [0|0] "" Vector__XXX
   SG_ BalCommand_10 : 8|8@1+ (1,0) [0|0] "" Vector__XXX
   SG_ BalCommand_11 : 16|8@1+ (1,0) [0|0] "" Vector__XXX
   SG_ BalCommand_12 : 24|8@1+ (1,0) [0|0] "" Vector__XXX

BO_ 441799732 P2_BMC_CMC_06_01: 8 BMC
   SG_ BalCommand_01 : 0|8@1+ (1,0) [0|0] "" Vector__XXX
   SG_ BalCommand_02 : 8|8@1+ (1,0) [0|0] "" Vector__XXX
   SG_ BalCommand_03 : 16|8@1+ (1,0) [0|0] "" Vector__XXX
   SG_ BalCommand_04 : 24|8@1+ (1,0) [0|0] "" Vector__XXX
   SG_ BalCommand_05 : 32|8@1+ (1,0) [0|0] "" Vector__XXX
   SG_ BalCommand_06 : 40|8@1+ (1,0) [0|0] "" Vector__XXX
   SG_ BalCommand_07 : 48|8@1+ (1,0) [0|0] "" Vector__XXX
   SG_ BalCommand_08 : 56|8@1+ (1,0) [0|0] "" Vector__XXX

BO_ 441799733 P2_BMC_CMC_06_02: 8 BMC
   SG_ BalCommand_09 : 0|8@1+ (1,0) [0|0] "" Vector__XXX
   SG_ BalCommand_10 : 8|8@1+ (1,0) [0|0] "" Vector__XXX
   SG_ BalCommand_11 : 16|8@1+ (1,0) [0|0] "" Vector__XXX
   SG_ BalCommand_12 : 24|8@1+ (1,0) [0|0] "" Vector__XXX

BO_ 441799734 P2_BMC_CMC_07_01: 8 BMC
   SG_ BalCommand_01 : 0|8@1+ (1,0) [0|0] "" Vector__XXX
   SG_ BalCommand_02 : 8|8@1+ (1,0) [0|0] "" Vector__XXX
   SG_ BalCommand_03 : 16|8@1+ (1,0) [0|0] "" Vector__XXX
   SG_ BalCommand_04 : 24|8@1+ (1,0) [0|0] "" Vector__XXX
   SG_ BalCommand_05 : 32|8@1+ (1,0) [0|0] "" Vector__XXX
   SG_ BalCommand_06 : 40|8@1+ (1,0) [0|0] "" Vector__XXX
   SG_ BalCommand_07 : 48|8@1+ (1,0) [0|0] "" Vector__XXX
   SG_ BalCommand_08 : 56|8@1+ (1,0) [0|0] "" Vector__XXX

BO_ 441799735 P2_BMC_CMC_07_02: 8 BMC
   SG_ BalCommand_09 : 0|8@1+ (1,0) [0|0] "" Vector__XXX
   SG_ BalCommand_10 : 8|8@1+ (1,0) [0|0] "" Vector__XXX
   SG_ BalCommand_11 : 16|8@1+ (1,0) [0|0] "" Vector__XXX
   SG_ BalCommand_12 : 24|8@1+ (1,0) [0|0] "" Vector__XXX

BO_ 441799736 P2_BMC_CMC_08_01: 8 BMC
   SG_ BalCommand_01 : 0|8@1+ (1,0) [0|0] "" Vector__XXX
   SG_ BalCommand_02 : 8|8@1+ (1,0) [0|0] "" Vector__XXX
   SG_ BalCommand_03 : 16|8@1+ (1,0) [0|0] "" Vector__XXX
   SG_ BalCommand_04 : 24|8@1+ (1,0) [0|0] "" Vector__XXX
   SG_ BalCommand_05 : 32|8@1+ (1,0) [0|0] "" Vector__XXX
   SG_ BalCommand_06 : 40|8@1+ (1,0) [0|0] "" Vector__XXX
   SG_ BalCommand_07 : 48|8@1+ (1,0) [0|0] "" Vector__XXX
   SG_ BalCommand_08 : 56|8@1+ (1,0) [0|0] "" Vector__XXX

BO_ 441799737 P2_BMC_CMC_08_02: 8 BMC
   SG_ BalCommand_09 : 0|8@1+ (1,0) [0|0] "" Vector__XXX
   SG_ BalCommand_10 : 8|8@1+ (1,0) [0|0] "" Vector__XXX
   SG_ BalCommand_11 : 16|8@1+ (1,0) [0|0] "" Vector__XXX
   SG_ BalCommand_12 : 24|8@1+ (1,0) [0|0] "" Vector__XXX

BO_ 441799720 P2_CMC_08_05: 8 Vector__XXX

BA_DEF_ BO_ "GenMsgBackgroundColor" STRING ;
BA_DEF_ BO_ "GenMsgForegroundColor" STRING ;
BA_DEF_DEF_ "GenMsgBackgroundColor" "#ffffff";
BA_DEF_DEF_ "GenMsgForegroundColor" "#000000";
